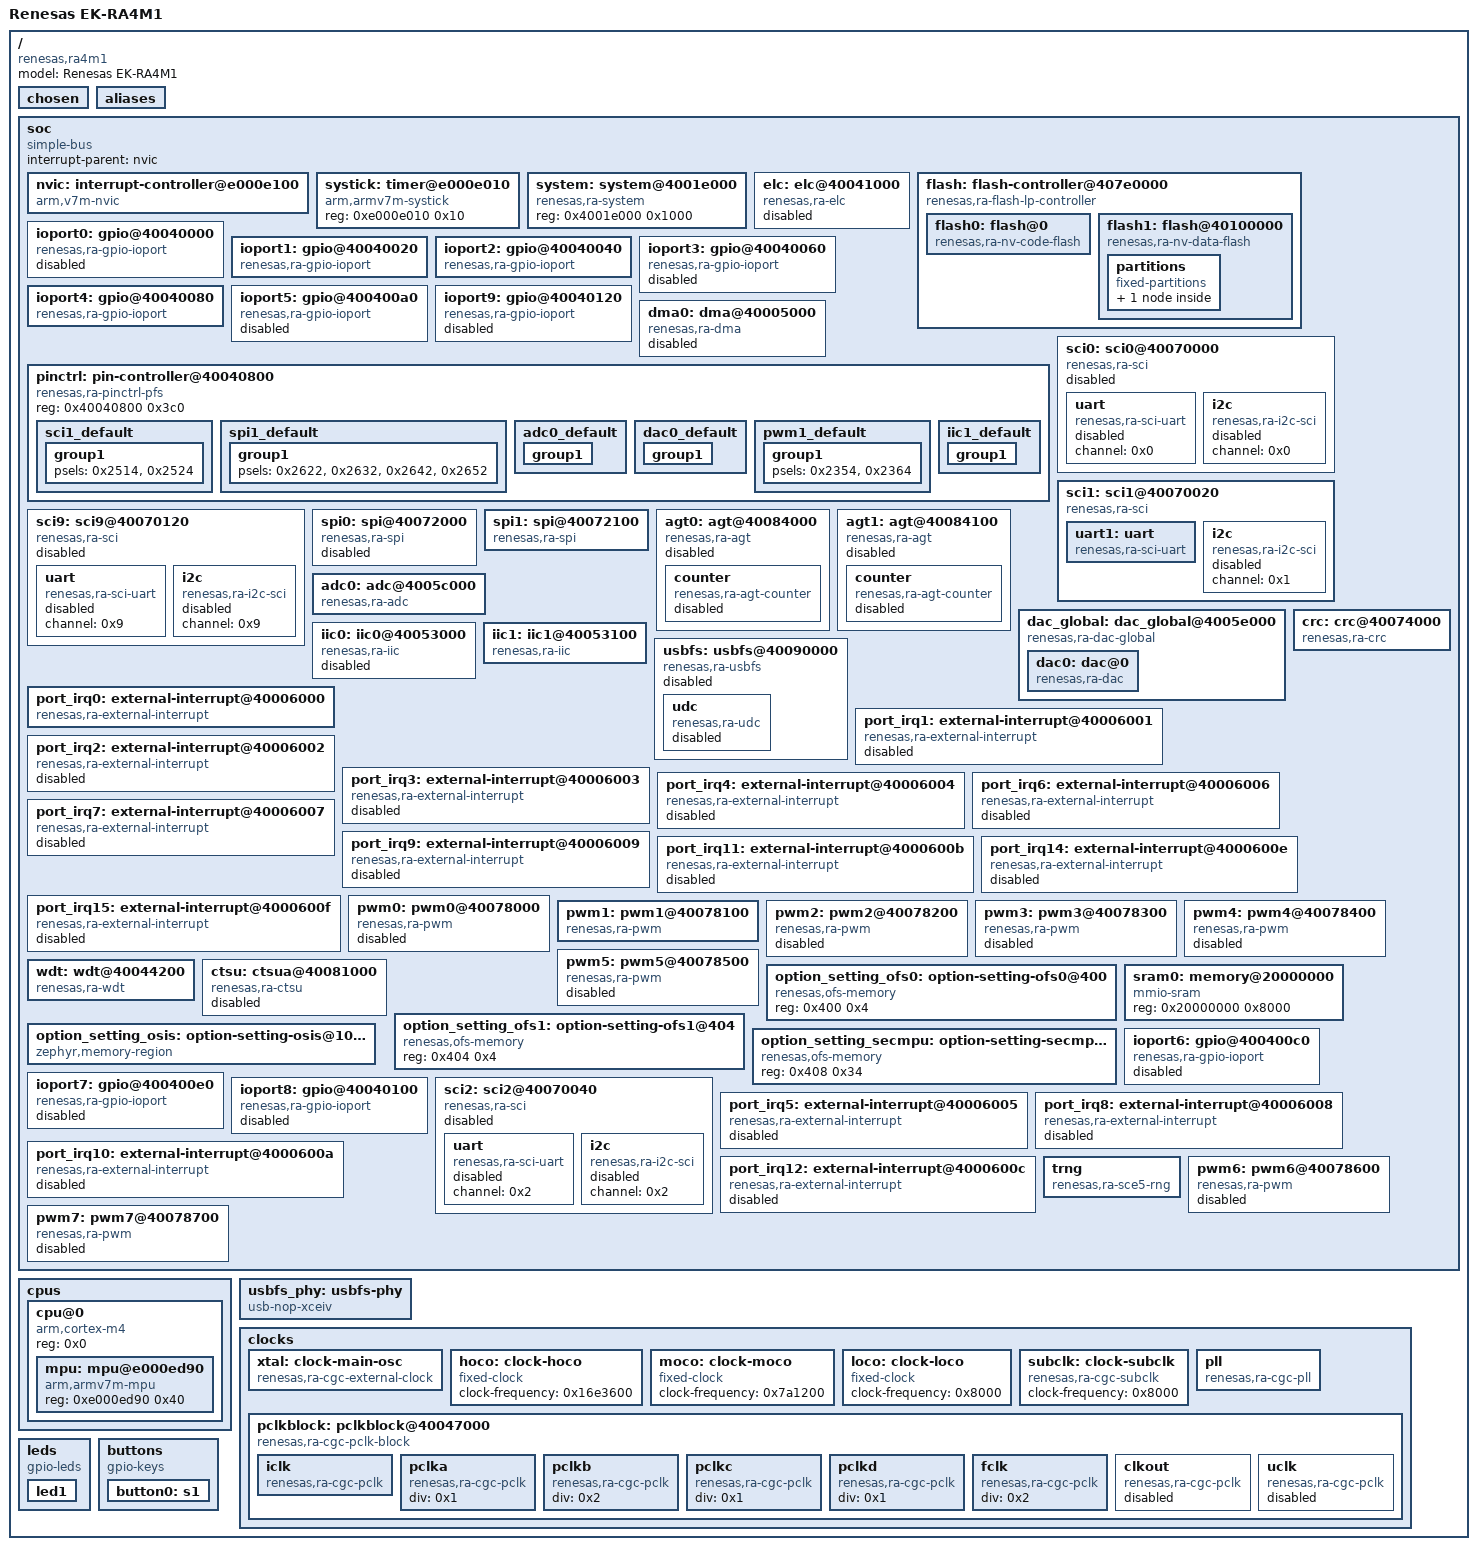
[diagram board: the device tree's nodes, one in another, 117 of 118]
/dts-v1/;

/* node '/' defined in zephyr/dts/common/skeleton.dtsi:9 */
/ {
	#address-cells = < 0x1 >;     /* in zephyr/dts/common/skeleton.dtsi:10 */
	#size-cells = < 0x1 >;        /* in zephyr/dts/common/skeleton.dtsi:11 */
	model = "Renesas EK-RA4M1";   /* in zephyr/boards/renesas/ek_ra4m1/ek_ra4m1.dts:15 */
	compatible = "renesas,ra4m1",
	             "renesas,ra";    /* in zephyr/boards/renesas/ek_ra4m1/ek_ra4m1.dts:16 */

	/* node '/chosen' defined in zephyr/dts/common/skeleton.dtsi:13 */
	chosen {
		zephyr,sram = &sram0;             /* in zephyr/boards/renesas/ek_ra4m1/ek_ra4m1.dts:19 */
		zephyr,flash-controller = &flash; /* in zephyr/boards/renesas/ek_ra4m1/ek_ra4m1.dts:20 */
		zephyr,flash = &flash0;           /* in zephyr/boards/renesas/ek_ra4m1/ek_ra4m1.dts:21 */
		zephyr,console = &uart1;          /* in zephyr/boards/renesas/ek_ra4m1/ek_ra4m1.dts:22 */
		zephyr,shell-uart = &uart1;       /* in zephyr/boards/renesas/ek_ra4m1/ek_ra4m1.dts:23 */
		zephyr,entropy = &trng;           /* in zephyr/boards/renesas/ek_ra4m1/ek_ra4m1.dts:24 */
		zephyr,crc = &crc;                /* in zephyr/boards/renesas/ek_ra4m1/ek_ra4m1.dts:25 */
	};

	/* node '/aliases' defined in zephyr/dts/common/skeleton.dtsi:15 */
	aliases {
		led0 = &led1;     /* in zephyr/boards/renesas/ek_ra4m1/ek_ra4m1.dts:48 */
		sw0 = &button0;   /* in zephyr/boards/renesas/ek_ra4m1/ek_ra4m1.dts:49 */
		watchdog0 = &wdt; /* in zephyr/boards/renesas/ek_ra4m1/ek_ra4m1.dts:50 */
	};

	/* node '/soc' defined in zephyr/dts/arm/armv7-m.dtsi:6 */
	soc {
		#address-cells = < 0x1 >;     /* in zephyr/dts/arm/armv7-m.dtsi:7 */
		#size-cells = < 0x1 >;        /* in zephyr/dts/arm/armv7-m.dtsi:8 */
		compatible = "simple-bus";    /* in zephyr/dts/arm/armv7-m.dtsi:9 */
		interrupt-parent = < &nvic >; /* in zephyr/dts/arm/armv7-m.dtsi:10 */
		ranges;                       /* in zephyr/dts/arm/armv7-m.dtsi:11 */

		/* node '/soc/interrupt-controller@e000e100' defined in zephyr/dts/arm/armv7-m.dtsi:13 */
		nvic: interrupt-controller@e000e100 {
			#address-cells = < 0x1 >;            /* in zephyr/dts/arm/armv7-m.dtsi:14 */
			compatible = "arm,v7m-nvic";         /* in zephyr/dts/arm/armv7-m.dtsi:15 */
			reg = < 0xe000e100 0xc00 >;          /* in zephyr/dts/arm/armv7-m.dtsi:16 */
			interrupt-controller;                /* in zephyr/dts/arm/armv7-m.dtsi:17 */
			#interrupt-cells = < 0x2 >;          /* in zephyr/dts/arm/armv7-m.dtsi:18 */
			arm,num-irq-priority-bits = < 0x4 >; /* in zephyr/dts/arm/renesas/ra/ra4/ra4-cm4-common.dtsi:526 */
			phandle = < 0x1 >;                   /* in zephyr/dts/arm/armv7-m.dtsi:10 */
		};

		/* node '/soc/timer@e000e010' defined in zephyr/dts/arm/armv7-m.dtsi:21 */
		systick: timer@e000e010 {
			compatible = "arm,armv7m-systick"; /* in zephyr/dts/arm/armv7-m.dtsi:22 */
			reg = < 0xe000e010 0x10 >;         /* in zephyr/dts/arm/armv7-m.dtsi:23 */
		};

		/* node '/soc/system@4001e000' defined in zephyr/dts/arm/renesas/ra/ra4/ra4-cm4-common.dtsi:33 */
		system: system@4001e000 {
			compatible = "renesas,ra-system"; /* in zephyr/dts/arm/renesas/ra/ra4/ra4-cm4-common.dtsi:34 */
			reg = < 0x4001e000 0x1000 >;      /* in zephyr/dts/arm/renesas/ra/ra4/ra4-cm4-common.dtsi:35 */
			status = "okay";                  /* in zephyr/dts/arm/renesas/ra/ra4/ra4-cm4-common.dtsi:36 */
		};

		/* node '/soc/elc@40041000' defined in zephyr/dts/arm/renesas/ra/ra4/ra4-cm4-common.dtsi:39 */
		elc: elc@40041000 {
			compatible = "renesas,ra-elc"; /* in zephyr/dts/arm/renesas/ra/ra4/ra4-cm4-common.dtsi:40 */
			reg = < 0x40041000 0x70 >;     /* in zephyr/dts/arm/renesas/ra/ra4/ra4-cm4-common.dtsi:41 */
			#renesas-elc-cells = < 0x2 >;  /* in zephyr/dts/arm/renesas/ra/ra4/ra4-cm4-common.dtsi:42 */
			clocks = < &pclkb 0x2 0xe >;   /* in zephyr/dts/arm/renesas/ra/ra4/ra4-cm4-common.dtsi:43 */
			status = "disabled";           /* in zephyr/dts/arm/renesas/ra/ra4/ra4-cm4-common.dtsi:44 */
		};

		/* node '/soc/flash-controller@407e0000' defined in zephyr/dts/arm/renesas/ra/ra4/ra4-cm4-common.dtsi:47 */
		flash: flash-controller@407e0000 {
			compatible = "renesas,ra-flash-lp-controller"; /* in zephyr/dts/arm/renesas/ra/ra4/ra4-cm4-common.dtsi:48 */
			reg = < 0x407e0000 0x10000 >;                  /* in zephyr/dts/arm/renesas/ra/ra4/ra4-cm4-common.dtsi:49 */
			#address-cells = < 0x1 >;                      /* in zephyr/dts/arm/renesas/ra/ra4/ra4-cm4-common.dtsi:50 */
			#size-cells = < 0x1 >;                         /* in zephyr/dts/arm/renesas/ra/ra4/ra4-cm4-common.dtsi:51 */
			interrupts = < 0x17 0x1 >;                     /* in zephyr/dts/arm/renesas/ra/ra4/ra4-cm4-common.dtsi:52 */
			interrupt-names = "frdyi";                     /* in zephyr/dts/arm/renesas/ra/ra4/ra4-cm4-common.dtsi:53 */
			flash-hardware-version = < 0x3 >;              /* in zephyr/dts/arm/renesas/ra/ra4/r7fa4m1ab3cfp.dtsi:14 */
			#erase-block-cells = < 0x2 >;                  /* in zephyr/dts/arm/renesas/ra/ra4/r7fa4m1ab3cfp.dtsi:15 */
			phandle = < 0x3 >;                             /* in zephyr/dts/arm/renesas/ra/ra4/r7fa4m1ab3cfp.dtsi:22 */

			/* node '/soc/flash-controller@407e0000/flash@0' defined in zephyr/dts/arm/renesas/ra/ra4/r7fa4m1ab3cfp.dtsi:17 */
			flash0: flash@0 {
				compatible = "renesas,ra-nv-code-flash"; /* in zephyr/dts/arm/renesas/ra/ra4/r7fa4m1ab3cfp.dtsi:18 */
				reg = < 0x0 0x40000 >;                   /* in zephyr/dts/arm/renesas/ra/ra4/r7fa4m1ab3cfp.dtsi:19 */
				write-block-size = < 0x8 >;              /* in zephyr/dts/arm/renesas/ra/ra4/r7fa4m1ab3cfp.dtsi:20 */
				erase-block-size = < 0x800 >;            /* in zephyr/dts/arm/renesas/ra/ra4/r7fa4m1ab3cfp.dtsi:21 */
				erase-blocks = < &flash 0x80 0x800 >;    /* in zephyr/dts/arm/renesas/ra/ra4/r7fa4m1ab3cfp.dtsi:22 */
				programming-enable;                      /* in zephyr/dts/arm/renesas/ra/ra4/r7fa4m1ab3cfp.dtsi:23 */
			};

			/* node '/soc/flash-controller@407e0000/flash@40100000' defined in zephyr/dts/arm/renesas/ra/ra4/r7fa4m1ab3cfp.dtsi:26 */
			flash1: flash@40100000 {
				compatible = "renesas,ra-nv-data-flash"; /* in zephyr/dts/arm/renesas/ra/ra4/r7fa4m1ab3cfp.dtsi:27 */
				reg = < 0x40100000 0x2000 >;             /* in zephyr/dts/arm/renesas/ra/ra4/r7fa4m1ab3cfp.dtsi:28 */
				write-block-size = < 0x1 >;              /* in zephyr/dts/arm/renesas/ra/ra4/r7fa4m1ab3cfp.dtsi:29 */
				erase-block-size = < 0x400 >;            /* in zephyr/dts/arm/renesas/ra/ra4/r7fa4m1ab3cfp.dtsi:30 */
				programming-enable;                      /* in zephyr/dts/arm/renesas/ra/ra4/r7fa4m1ab3cfp.dtsi:31 */

				/* node '/soc/flash-controller@407e0000/flash@40100000/partitions' defined in zephyr/boards/renesas/ek_ra4m1/ek_ra4m1.dts:150 */
				partitions {
					compatible = "fixed-partitions"; /* in zephyr/boards/renesas/ek_ra4m1/ek_ra4m1.dts:151 */
					#address-cells = < 0x1 >;        /* in zephyr/boards/renesas/ek_ra4m1/ek_ra4m1.dts:152 */
					#size-cells = < 0x1 >;           /* in zephyr/boards/renesas/ek_ra4m1/ek_ra4m1.dts:153 */

					/* node '/soc/flash-controller@407e0000/flash@40100000/partitions/partition@0' defined in zephyr/boards/renesas/ek_ra4m1/ek_ra4m1.dts:155 */
					storage_partition: partition@0 {
						label = "storage";    /* in zephyr/boards/renesas/ek_ra4m1/ek_ra4m1.dts:156 */
						reg = < 0x0 0x2000 >; /* in zephyr/boards/renesas/ek_ra4m1/ek_ra4m1.dts:157 */
					};
				};
			};
		};

		/* node '/soc/gpio@40040000' defined in zephyr/dts/arm/renesas/ra/ra4/ra4-cm4-common.dtsi:56 */
		ioport0: gpio@40040000 {
			compatible = "renesas,ra-gpio-ioport";                                               /* in zephyr/dts/arm/renesas/ra/ra4/ra4-cm4-common.dtsi:57 */
			reg = < 0x40040000 0x20 >;                                                           /* in zephyr/dts/arm/renesas/ra/ra4/ra4-cm4-common.dtsi:58 */
			port = < 0x0 >;                                                                      /* in zephyr/dts/arm/renesas/ra/ra4/ra4-cm4-common.dtsi:59 */
			gpio-controller;                                                                     /* in zephyr/dts/arm/renesas/ra/ra4/ra4-cm4-common.dtsi:60 */
			#gpio-cells = < 0x2 >;                                                               /* in zephyr/dts/arm/renesas/ra/ra4/ra4-cm4-common.dtsi:61 */
			ngpios = < 0x10 >;                                                                   /* in zephyr/dts/arm/renesas/ra/ra4/ra4-cm4-common.dtsi:62 */
			status = "disabled";                                                                 /* in zephyr/dts/arm/renesas/ra/ra4/ra4-cm4-common.dtsi:63 */
			port-irqs = < &port_irq2 &port_irq3 &port_irq6 &port_irq7 &port_irq10 &port_irq15 >; /* in zephyr/dts/arm/renesas/ra/ra4/r7fa4m1ax.dtsi:253 */
			port-irq-names = "port-irq2",
			                 "port-irq3",
			                 "port-irq6",
			                 "port-irq7",
			                 "port-irq10",
			                 "port-irq15";                                                       /* in zephyr/dts/arm/renesas/ra/ra4/r7fa4m1ax.dtsi:255 */
			port-irq2-pins = < 0x2 >;                                                            /* in zephyr/dts/arm/renesas/ra/ra4/r7fa4m1ax.dtsi:261 */
			port-irq3-pins = < 0x4 >;                                                            /* in zephyr/dts/arm/renesas/ra/ra4/r7fa4m1ax.dtsi:262 */
			port-irq6-pins = < 0x0 >;                                                            /* in zephyr/dts/arm/renesas/ra/ra4/r7fa4m1ax.dtsi:263 */
			port-irq7-pins = < 0x1 0xf >;                                                        /* in zephyr/dts/arm/renesas/ra/ra4/r7fa4m1ax.dtsi:264 */
			port-irq10-pins = < 0x5 >;                                                           /* in zephyr/dts/arm/renesas/ra/ra4/r7fa4m1ax.dtsi:265 */
			port-irq15-pins = < 0xb >;                                                           /* in zephyr/dts/arm/renesas/ra/ra4/r7fa4m1ax.dtsi:266 */
		};

		/* node '/soc/gpio@40040020' defined in zephyr/dts/arm/renesas/ra/ra4/ra4-cm4-common.dtsi:66 */
		ioport1: gpio@40040020 {
			compatible = "renesas,ra-gpio-ioport";                                  /* in zephyr/dts/arm/renesas/ra/ra4/ra4-cm4-common.dtsi:67 */
			reg = < 0x40040020 0x20 >;                                              /* in zephyr/dts/arm/renesas/ra/ra4/ra4-cm4-common.dtsi:68 */
			port = < 0x1 >;                                                         /* in zephyr/dts/arm/renesas/ra/ra4/ra4-cm4-common.dtsi:69 */
			gpio-controller;                                                        /* in zephyr/dts/arm/renesas/ra/ra4/ra4-cm4-common.dtsi:70 */
			#gpio-cells = < 0x2 >;                                                  /* in zephyr/dts/arm/renesas/ra/ra4/ra4-cm4-common.dtsi:71 */
			ngpios = < 0x10 >;                                                      /* in zephyr/dts/arm/renesas/ra/ra4/ra4-cm4-common.dtsi:72 */
			port-irqs = < &port_irq0 &port_irq1 &port_irq2 &port_irq3 &port_irq4 >; /* in zephyr/dts/arm/renesas/ra/ra4/r7fa4m1ax.dtsi:270 */
			port-irq-names = "port-irq0",
			                 "port-irq1",
			                 "port-irq2",
			                 "port-irq3",
			                 "port-irq4";                                           /* in zephyr/dts/arm/renesas/ra/ra4/r7fa4m1ax.dtsi:272 */
			port-irq0-pins = < 0x5 >;                                               /* in zephyr/dts/arm/renesas/ra/ra4/r7fa4m1ax.dtsi:277 */
			port-irq1-pins = < 0x1 0x4 >;                                           /* in zephyr/dts/arm/renesas/ra/ra4/r7fa4m1ax.dtsi:278 */
			port-irq2-pins = < 0x0 >;                                               /* in zephyr/dts/arm/renesas/ra/ra4/r7fa4m1ax.dtsi:279 */
			port-irq3-pins = < 0xa >;                                               /* in zephyr/dts/arm/renesas/ra/ra4/r7fa4m1ax.dtsi:280 */
			port-irq4-pins = < 0xb >;                                               /* in zephyr/dts/arm/renesas/ra/ra4/r7fa4m1ax.dtsi:281 */
			status = "okay";                                                        /* in zephyr/boards/renesas/ek_ra4m1/ek_ra4m1.dts:84 */
			phandle = < 0x20 >;                                                     /* in zephyr/boards/renesas/ek_ra4m1/ek_ra4m1.dts:32 */
		};

		/* node '/soc/gpio@40040040' defined in zephyr/dts/arm/renesas/ra/ra4/ra4-cm4-common.dtsi:76 */
		ioport2: gpio@40040040 {
			compatible = "renesas,ra-gpio-ioport";                       /* in zephyr/dts/arm/renesas/ra/ra4/ra4-cm4-common.dtsi:77 */
			reg = < 0x40040040 0x20 >;                                   /* in zephyr/dts/arm/renesas/ra/ra4/ra4-cm4-common.dtsi:78 */
			port = < 0x2 >;                                              /* in zephyr/dts/arm/renesas/ra/ra4/ra4-cm4-common.dtsi:79 */
			gpio-controller;                                             /* in zephyr/dts/arm/renesas/ra/ra4/ra4-cm4-common.dtsi:80 */
			#gpio-cells = < 0x2 >;                                       /* in zephyr/dts/arm/renesas/ra/ra4/ra4-cm4-common.dtsi:81 */
			ngpios = < 0x10 >;                                           /* in zephyr/dts/arm/renesas/ra/ra4/ra4-cm4-common.dtsi:82 */
			port-irqs = < &port_irq0 &port_irq1 &port_irq2 &port_irq3 >; /* in zephyr/dts/arm/renesas/ra/ra4/r7fa4m1ax.dtsi:285 */
			port-irq-names = "port-irq0",
			                 "port-irq1",
			                 "port-irq2",
			                 "port-irq3";                                /* in zephyr/dts/arm/renesas/ra/ra4/r7fa4m1ax.dtsi:287 */
			port-irq0-pins = < 0x6 >;                                    /* in zephyr/dts/arm/renesas/ra/ra4/r7fa4m1ax.dtsi:291 */
			port-irq1-pins = < 0x5 >;                                    /* in zephyr/dts/arm/renesas/ra/ra4/r7fa4m1ax.dtsi:292 */
			port-irq2-pins = < 0xd >;                                    /* in zephyr/dts/arm/renesas/ra/ra4/r7fa4m1ax.dtsi:293 */
			port-irq3-pins = < 0xc >;                                    /* in zephyr/dts/arm/renesas/ra/ra4/r7fa4m1ax.dtsi:294 */
			status = "okay";                                             /* in zephyr/boards/renesas/ek_ra4m1/ek_ra4m1.dts:88 */
		};

		/* node '/soc/gpio@40040060' defined in zephyr/dts/arm/renesas/ra/ra4/ra4-cm4-common.dtsi:86 */
		ioport3: gpio@40040060 {
			compatible = "renesas,ra-gpio-ioport";                       /* in zephyr/dts/arm/renesas/ra/ra4/ra4-cm4-common.dtsi:87 */
			reg = < 0x40040060 0x20 >;                                   /* in zephyr/dts/arm/renesas/ra/ra4/ra4-cm4-common.dtsi:88 */
			port = < 0x3 >;                                              /* in zephyr/dts/arm/renesas/ra/ra4/ra4-cm4-common.dtsi:89 */
			gpio-controller;                                             /* in zephyr/dts/arm/renesas/ra/ra4/ra4-cm4-common.dtsi:90 */
			#gpio-cells = < 0x2 >;                                       /* in zephyr/dts/arm/renesas/ra/ra4/ra4-cm4-common.dtsi:91 */
			ngpios = < 0x10 >;                                           /* in zephyr/dts/arm/renesas/ra/ra4/ra4-cm4-common.dtsi:92 */
			status = "disabled";                                         /* in zephyr/dts/arm/renesas/ra/ra4/ra4-cm4-common.dtsi:93 */
			port-irqs = < &port_irq5 &port_irq6 &port_irq8 &port_irq9 >; /* in zephyr/dts/arm/renesas/ra/ra4/r7fa4m1ax.dtsi:298 */
			port-irq-names = "port-irq5",
			                 "port-irq6",
			                 "port-irq8",
			                 "port-irq9";                                /* in zephyr/dts/arm/renesas/ra/ra4/r7fa4m1ax.dtsi:300 */
			port-irq5-pins = < 0x2 >;                                    /* in zephyr/dts/arm/renesas/ra/ra4/r7fa4m1ax.dtsi:304 */
			port-irq6-pins = < 0x1 >;                                    /* in zephyr/dts/arm/renesas/ra/ra4/r7fa4m1ax.dtsi:305 */
			port-irq8-pins = < 0x5 >;                                    /* in zephyr/dts/arm/renesas/ra/ra4/r7fa4m1ax.dtsi:306 */
			port-irq9-pins = < 0x4 >;                                    /* in zephyr/dts/arm/renesas/ra/ra4/r7fa4m1ax.dtsi:307 */
		};

		/* node '/soc/gpio@40040080' defined in zephyr/dts/arm/renesas/ra/ra4/ra4-cm4-common.dtsi:96 */
		ioport4: gpio@40040080 {
			compatible = "renesas,ra-gpio-ioport";                                                        /* in zephyr/dts/arm/renesas/ra/ra4/ra4-cm4-common.dtsi:97 */
			reg = < 0x40040080 0x20 >;                                                                    /* in zephyr/dts/arm/renesas/ra/ra4/ra4-cm4-common.dtsi:98 */
			port = < 0x4 >;                                                                               /* in zephyr/dts/arm/renesas/ra/ra4/ra4-cm4-common.dtsi:99 */
			gpio-controller;                                                                              /* in zephyr/dts/arm/renesas/ra/ra4/ra4-cm4-common.dtsi:100 */
			#gpio-cells = < 0x2 >;                                                                        /* in zephyr/dts/arm/renesas/ra/ra4/ra4-cm4-common.dtsi:101 */
			ngpios = < 0x10 >;                                                                            /* in zephyr/dts/arm/renesas/ra/ra4/ra4-cm4-common.dtsi:102 */
			vbatts-pins = < 0x2 0x3 0x4 >;                                                                /* in zephyr/dts/arm/renesas/ra/ra4/ra4-cm4-common.dtsi:103 */
			port-irqs = < &port_irq0 &port_irq4 &port_irq5 &port_irq6 &port_irq7 &port_irq8 &port_irq9 >; /* in zephyr/dts/arm/renesas/ra/ra4/r7fa4m1ax.dtsi:311 */
			port-irq-names = "port-irq0",
			                 "port-irq4",
			                 "port-irq5",
			                 "port-irq6",
			                 "port-irq7",
			                 "port-irq8",
			                 "port-irq9";                                                                 /* in zephyr/dts/arm/renesas/ra/ra4/r7fa4m1ax.dtsi:314 */
			port-irq0-pins = < 0x0 >;                                                                     /* in zephyr/dts/arm/renesas/ra/ra4/r7fa4m1ax.dtsi:321 */
			port-irq4-pins = < 0x2 0xb >;                                                                 /* in zephyr/dts/arm/renesas/ra/ra4/r7fa4m1ax.dtsi:322 */
			port-irq5-pins = < 0x1 0xa >;                                                                 /* in zephyr/dts/arm/renesas/ra/ra4/r7fa4m1ax.dtsi:323 */
			port-irq6-pins = < 0x9 >;                                                                     /* in zephyr/dts/arm/renesas/ra/ra4/r7fa4m1ax.dtsi:324 */
			port-irq7-pins = < 0x8 >;                                                                     /* in zephyr/dts/arm/renesas/ra/ra4/r7fa4m1ax.dtsi:325 */
			port-irq8-pins = < 0xf >;                                                                     /* in zephyr/dts/arm/renesas/ra/ra4/r7fa4m1ax.dtsi:326 */
			port-irq9-pins = < 0xe >;                                                                     /* in zephyr/dts/arm/renesas/ra/ra4/r7fa4m1ax.dtsi:327 */
			status = "okay";                                                                              /* in zephyr/boards/renesas/ek_ra4m1/ek_ra4m1.dts:92 */
		};

		/* node '/soc/gpio@400400a0' defined in zephyr/dts/arm/renesas/ra/ra4/ra4-cm4-common.dtsi:107 */
		ioport5: gpio@400400a0 {
			compatible = "renesas,ra-gpio-ioport";               /* in zephyr/dts/arm/renesas/ra/ra4/ra4-cm4-common.dtsi:108 */
			reg = < 0x400400a0 0x20 >;                           /* in zephyr/dts/arm/renesas/ra/ra4/ra4-cm4-common.dtsi:109 */
			port = < 0x5 >;                                      /* in zephyr/dts/arm/renesas/ra/ra4/ra4-cm4-common.dtsi:110 */
			gpio-controller;                                     /* in zephyr/dts/arm/renesas/ra/ra4/ra4-cm4-common.dtsi:111 */
			#gpio-cells = < 0x2 >;                               /* in zephyr/dts/arm/renesas/ra/ra4/ra4-cm4-common.dtsi:112 */
			ngpios = < 0x10 >;                                   /* in zephyr/dts/arm/renesas/ra/ra4/ra4-cm4-common.dtsi:113 */
			status = "disabled";                                 /* in zephyr/dts/arm/renesas/ra/ra4/ra4-cm4-common.dtsi:114 */
			port-irqs = < &port_irq11 &port_irq12 &port_irq14 >; /* in zephyr/dts/arm/renesas/ra/ra4/r7fa4m1ax.dtsi:331 */
			port-irq-names = "port-irq11",
			                 "port-irq12",
			                 "port-irq14";                       /* in zephyr/dts/arm/renesas/ra/ra4/r7fa4m1ax.dtsi:332 */
			port-irq11-pins = < 0x1 >;                           /* in zephyr/dts/arm/renesas/ra/ra4/r7fa4m1ax.dtsi:335 */
			port-irq12-pins = < 0x2 >;                           /* in zephyr/dts/arm/renesas/ra/ra4/r7fa4m1ax.dtsi:336 */
			port-irq14-pins = < 0x5 >;                           /* in zephyr/dts/arm/renesas/ra/ra4/r7fa4m1ax.dtsi:337 */
		};

		/* node '/soc/gpio@40040120' defined in zephyr/dts/arm/renesas/ra/ra4/ra4-cm4-common.dtsi:117 */
		ioport9: gpio@40040120 {
			compatible = "renesas,ra-gpio-ioport"; /* in zephyr/dts/arm/renesas/ra/ra4/ra4-cm4-common.dtsi:118 */
			reg = < 0x40040120 0x20 >;             /* in zephyr/dts/arm/renesas/ra/ra4/ra4-cm4-common.dtsi:119 */
			port = < 0x9 >;                        /* in zephyr/dts/arm/renesas/ra/ra4/ra4-cm4-common.dtsi:120 */
			gpio-controller;                       /* in zephyr/dts/arm/renesas/ra/ra4/ra4-cm4-common.dtsi:121 */
			#gpio-cells = < 0x2 >;                 /* in zephyr/dts/arm/renesas/ra/ra4/ra4-cm4-common.dtsi:122 */
			ngpios = < 0x10 >;                     /* in zephyr/dts/arm/renesas/ra/ra4/ra4-cm4-common.dtsi:123 */
			status = "disabled";                   /* in zephyr/dts/arm/renesas/ra/ra4/ra4-cm4-common.dtsi:124 */
		};

		/* node '/soc/dma@40005000' defined in zephyr/dts/arm/renesas/ra/ra4/ra4-cm4-common.dtsi:127 */
		dma0: dma@40005000 {
			compatible = "renesas,ra-dma"; /* in zephyr/dts/arm/renesas/ra/ra4/ra4-cm4-common.dtsi:128 */
			reg = < 0x40005000 0x100 >,
			      < 0x40005200 0xa0 >;     /* in zephyr/dts/arm/renesas/ra/ra4/ra4-cm4-common.dtsi:129 */
			reg-names = "channel",
			            "common";          /* in zephyr/dts/arm/renesas/ra/ra4/ra4-cm4-common.dtsi:130 */
			clocks = < &iclk 0x0 0x16 >;   /* in zephyr/dts/arm/renesas/ra/ra4/ra4-cm4-common.dtsi:131 */
			dma-channels = < 0x4 >;        /* in zephyr/dts/arm/renesas/ra/ra4/ra4-cm4-common.dtsi:132 */
			#dma-cells = < 0x2 >;          /* in zephyr/dts/arm/renesas/ra/ra4/ra4-cm4-common.dtsi:133 */
			status = "disabled";           /* in zephyr/dts/arm/renesas/ra/ra4/ra4-cm4-common.dtsi:134 */
		};

		/* node '/soc/pin-controller@40040800' defined in zephyr/dts/arm/renesas/ra/ra4/ra4-cm4-common.dtsi:137 */
		pinctrl: pin-controller@40040800 {
			compatible = "renesas,ra-pinctrl-pfs"; /* in zephyr/dts/arm/renesas/ra/ra4/ra4-cm4-common.dtsi:138 */
			reg = < 0x40040800 0x3c0 >;            /* in zephyr/dts/arm/renesas/ra/ra4/ra4-cm4-common.dtsi:139 */
			status = "okay";                       /* in zephyr/dts/arm/renesas/ra/ra4/ra4-cm4-common.dtsi:140 */

			/* node '/soc/pin-controller@40040800/sci1_default' defined in zephyr/boards/renesas/ek_ra4m1/ek_ra4m1-pinctrl.dtsi:7 */
			sci1_default: sci1_default {
				phandle = < 0x15 >; /* in zephyr/boards/renesas/ek_ra4m1/ek_ra4m1.dts:73 */

				/* node '/soc/pin-controller@40040800/sci1_default/group1' defined in zephyr/boards/renesas/ek_ra4m1/ek_ra4m1-pinctrl.dtsi:8 */
				group1 {
					psels = < 0x2514 >,
					        < 0x2524 >; /* in zephyr/boards/renesas/ek_ra4m1/ek_ra4m1-pinctrl.dtsi:10 */
				};
			};

			/* node '/soc/pin-controller@40040800/spi1_default' defined in zephyr/boards/renesas/ek_ra4m1/ek_ra4m1-pinctrl.dtsi:15 */
			spi1_default: spi1_default {
				phandle = < 0x16 >; /* in zephyr/boards/renesas/ek_ra4m1/ek_ra4m1.dts:96 */

				/* node '/soc/pin-controller@40040800/spi1_default/group1' defined in zephyr/boards/renesas/ek_ra4m1/ek_ra4m1-pinctrl.dtsi:16 */
				group1 {
					psels = < 0x2622 >,
					        < 0x2632 >,
					        < 0x2642 >,
					        < 0x2652 >; /* in zephyr/boards/renesas/ek_ra4m1/ek_ra4m1-pinctrl.dtsi:18 */
				};
			};

			/* node '/soc/pin-controller@40040800/adc0_default' defined in zephyr/boards/renesas/ek_ra4m1/ek_ra4m1-pinctrl.dtsi:25 */
			adc0_default: adc0_default {
				phandle = < 0x17 >; /* in zephyr/boards/renesas/ek_ra4m1/ek_ra4m1.dts:103 */

				/* node '/soc/pin-controller@40040800/adc0_default/group1' defined in zephyr/boards/renesas/ek_ra4m1/ek_ra4m1-pinctrl.dtsi:26 */
				group1 {
					psels = < 0x2000 >;    /* in zephyr/boards/renesas/ek_ra4m1/ek_ra4m1-pinctrl.dtsi:28 */
					renesas,analog-enable; /* in zephyr/boards/renesas/ek_ra4m1/ek_ra4m1-pinctrl.dtsi:29 */
				};
			};

			/* node '/soc/pin-controller@40040800/dac0_default' defined in zephyr/boards/renesas/ek_ra4m1/ek_ra4m1-pinctrl.dtsi:33 */
			dac0_default: dac0_default {
				phandle = < 0x18 >; /* in zephyr/boards/renesas/ek_ra4m1/ek_ra4m1.dts:108 */

				/* node '/soc/pin-controller@40040800/dac0_default/group1' defined in zephyr/boards/renesas/ek_ra4m1/ek_ra4m1-pinctrl.dtsi:34 */
				group1 {
					psels = < 0x20e0 >;    /* in zephyr/boards/renesas/ek_ra4m1/ek_ra4m1-pinctrl.dtsi:36 */
					renesas,analog-enable; /* in zephyr/boards/renesas/ek_ra4m1/ek_ra4m1-pinctrl.dtsi:37 */
				};
			};

			/* node '/soc/pin-controller@40040800/pwm1_default' defined in zephyr/boards/renesas/ek_ra4m1/ek_ra4m1-pinctrl.dtsi:41 */
			pwm1_default: pwm1_default {
				phandle = < 0x1d >; /* in zephyr/boards/renesas/ek_ra4m1/ek_ra4m1.dts:123 */

				/* node '/soc/pin-controller@40040800/pwm1_default/group1' defined in zephyr/boards/renesas/ek_ra4m1/ek_ra4m1-pinctrl.dtsi:42 */
				group1 {
					psels = < 0x2354 >,
					        < 0x2364 >; /* in zephyr/boards/renesas/ek_ra4m1/ek_ra4m1-pinctrl.dtsi:44 */
				};
			};

			/* node '/soc/pin-controller@40040800/iic1_default' defined in zephyr/boards/renesas/ek_ra4m1/ek_ra4m1-pinctrl.dtsi:49 */
			iic1_default: iic1_default {
				phandle = < 0x19 >; /* in zephyr/boards/renesas/ek_ra4m1/ek_ra4m1.dts:131 */

				/* node '/soc/pin-controller@40040800/iic1_default/group1' defined in zephyr/boards/renesas/ek_ra4m1/ek_ra4m1-pinctrl.dtsi:50 */
				group1 {
					psels = < 0x2701 >,
					        < 0x2762 >;        /* in zephyr/boards/renesas/ek_ra4m1/ek_ra4m1-pinctrl.dtsi:52 */
					drive-strength = "medium"; /* in zephyr/boards/renesas/ek_ra4m1/ek_ra4m1-pinctrl.dtsi:54 */
				};
			};
		};

		/* node '/soc/sci0@40070000' defined in zephyr/dts/arm/renesas/ra/ra4/ra4-cm4-common.dtsi:143 */
		sci0: sci0@40070000 {
			compatible = "renesas,ra-sci"; /* in zephyr/dts/arm/renesas/ra/ra4/ra4-cm4-common.dtsi:144 */
			interrupts = < 0x0 0x1 >,
			             < 0x1 0x1 >,
			             < 0x2 0x1 >,
			             < 0x3 0x1 >;      /* in zephyr/dts/arm/renesas/ra/ra4/ra4-cm4-common.dtsi:145 */
			interrupt-names = "rxi",
			                  "txi",
			                  "tei",
			                  "eri";       /* in zephyr/dts/arm/renesas/ra/ra4/ra4-cm4-common.dtsi:146 */
			reg = < 0x40070000 0x20 >;     /* in zephyr/dts/arm/renesas/ra/ra4/ra4-cm4-common.dtsi:147 */
			clocks = < &pclka 0x1 0x1f >;  /* in zephyr/dts/arm/renesas/ra/ra4/ra4-cm4-common.dtsi:148 */
			status = "disabled";           /* in zephyr/dts/arm/renesas/ra/ra4/ra4-cm4-common.dtsi:149 */

			/* node '/soc/sci0@40070000/uart' defined in zephyr/dts/arm/renesas/ra/ra4/ra4-cm4-common.dtsi:151 */
			uart {
				compatible = "renesas,ra-sci-uart"; /* in zephyr/dts/arm/renesas/ra/ra4/ra4-cm4-common.dtsi:152 */
				channel = < 0x0 >;                  /* in zephyr/dts/arm/renesas/ra/ra4/ra4-cm4-common.dtsi:153 */
				status = "disabled";                /* in zephyr/dts/arm/renesas/ra/ra4/ra4-cm4-common.dtsi:154 */
			};

			/* node '/soc/sci0@40070000/i2c' defined in zephyr/dts/arm/renesas/ra/ra4/ra4-cm4-common.dtsi:157 */
			i2c {
				compatible = "renesas,ra-i2c-sci"; /* in zephyr/dts/arm/renesas/ra/ra4/ra4-cm4-common.dtsi:158 */
				#address-cells = < 0x1 >;          /* in zephyr/dts/arm/renesas/ra/ra4/ra4-cm4-common.dtsi:159 */
				#size-cells = < 0x0 >;             /* in zephyr/dts/arm/renesas/ra/ra4/ra4-cm4-common.dtsi:160 */
				channel = < 0x0 >;                 /* in zephyr/dts/arm/renesas/ra/ra4/ra4-cm4-common.dtsi:161 */
				status = "disabled";               /* in zephyr/dts/arm/renesas/ra/ra4/ra4-cm4-common.dtsi:162 */
			};
		};

		/* node '/soc/sci1@40070020' defined in zephyr/dts/arm/renesas/ra/ra4/ra4-cm4-common.dtsi:166 */
		sci1: sci1@40070020 {
			compatible = "renesas,ra-sci"; /* in zephyr/dts/arm/renesas/ra/ra4/ra4-cm4-common.dtsi:167 */
			interrupts = < 0x4 0x1 >,
			             < 0x5 0x1 >,
			             < 0x6 0x1 >,
			             < 0x7 0x1 >;      /* in zephyr/dts/arm/renesas/ra/ra4/ra4-cm4-common.dtsi:168 */
			interrupt-names = "rxi",
			                  "txi",
			                  "tei",
			                  "eri";       /* in zephyr/dts/arm/renesas/ra/ra4/ra4-cm4-common.dtsi:169 */
			reg = < 0x40070020 0x20 >;     /* in zephyr/dts/arm/renesas/ra/ra4/ra4-cm4-common.dtsi:170 */
			clocks = < &pclka 0x1 0x1e >;  /* in zephyr/dts/arm/renesas/ra/ra4/ra4-cm4-common.dtsi:171 */
			pinctrl-0 = < &sci1_default >; /* in zephyr/boards/renesas/ek_ra4m1/ek_ra4m1.dts:73 */
			pinctrl-names = "default";     /* in zephyr/boards/renesas/ek_ra4m1/ek_ra4m1.dts:74 */
			status = "okay";               /* in zephyr/boards/renesas/ek_ra4m1/ek_ra4m1.dts:75 */

			/* node '/soc/sci1@40070020/uart' defined in zephyr/dts/arm/renesas/ra/ra4/ra4-cm4-common.dtsi:174 */
			uart1: uart {
				compatible = "renesas,ra-sci-uart"; /* in zephyr/dts/arm/renesas/ra/ra4/ra4-cm4-common.dtsi:175 */
				channel = < 0x1 >;                  /* in zephyr/dts/arm/renesas/ra/ra4/ra4-cm4-common.dtsi:176 */
				current-speed = < 0x1c200 >;        /* in zephyr/boards/renesas/ek_ra4m1/ek_ra4m1.dts:78 */
				status = "okay";                    /* in zephyr/boards/renesas/ek_ra4m1/ek_ra4m1.dts:79 */
			};

			/* node '/soc/sci1@40070020/i2c' defined in zephyr/dts/arm/renesas/ra/ra4/ra4-cm4-common.dtsi:180 */
			i2c {
				compatible = "renesas,ra-i2c-sci"; /* in zephyr/dts/arm/renesas/ra/ra4/ra4-cm4-common.dtsi:181 */
				#address-cells = < 0x1 >;          /* in zephyr/dts/arm/renesas/ra/ra4/ra4-cm4-common.dtsi:182 */
				#size-cells = < 0x0 >;             /* in zephyr/dts/arm/renesas/ra/ra4/ra4-cm4-common.dtsi:183 */
				channel = < 0x1 >;                 /* in zephyr/dts/arm/renesas/ra/ra4/ra4-cm4-common.dtsi:184 */
				status = "disabled";               /* in zephyr/dts/arm/renesas/ra/ra4/ra4-cm4-common.dtsi:185 */
			};
		};

		/* node '/soc/sci9@40070120' defined in zephyr/dts/arm/renesas/ra/ra4/ra4-cm4-common.dtsi:189 */
		sci9: sci9@40070120 {
			compatible = "renesas,ra-sci"; /* in zephyr/dts/arm/renesas/ra/ra4/ra4-cm4-common.dtsi:190 */
			reg = < 0x40070120 0x20 >;     /* in zephyr/dts/arm/renesas/ra/ra4/ra4-cm4-common.dtsi:191 */
			clocks = < &pclka 0x1 0x16 >;  /* in zephyr/dts/arm/renesas/ra/ra4/ra4-cm4-common.dtsi:192 */
			status = "disabled";           /* in zephyr/dts/arm/renesas/ra/ra4/ra4-cm4-common.dtsi:193 */

			/* node '/soc/sci9@40070120/uart' defined in zephyr/dts/arm/renesas/ra/ra4/ra4-cm4-common.dtsi:195 */
			uart {
				compatible = "renesas,ra-sci-uart"; /* in zephyr/dts/arm/renesas/ra/ra4/ra4-cm4-common.dtsi:196 */
				channel = < 0x9 >;                  /* in zephyr/dts/arm/renesas/ra/ra4/ra4-cm4-common.dtsi:197 */
				status = "disabled";                /* in zephyr/dts/arm/renesas/ra/ra4/ra4-cm4-common.dtsi:198 */
			};

			/* node '/soc/sci9@40070120/i2c' defined in zephyr/dts/arm/renesas/ra/ra4/ra4-cm4-common.dtsi:201 */
			i2c {
				compatible = "renesas,ra-i2c-sci"; /* in zephyr/dts/arm/renesas/ra/ra4/ra4-cm4-common.dtsi:202 */
				#address-cells = < 0x1 >;          /* in zephyr/dts/arm/renesas/ra/ra4/ra4-cm4-common.dtsi:203 */
				#size-cells = < 0x0 >;             /* in zephyr/dts/arm/renesas/ra/ra4/ra4-cm4-common.dtsi:204 */
				channel = < 0x9 >;                 /* in zephyr/dts/arm/renesas/ra/ra4/ra4-cm4-common.dtsi:205 */
				status = "disabled";               /* in zephyr/dts/arm/renesas/ra/ra4/ra4-cm4-common.dtsi:206 */
			};
		};

		/* node '/soc/spi@40072000' defined in zephyr/dts/arm/renesas/ra/ra4/ra4-cm4-common.dtsi:210 */
		spi0: spi@40072000 {
			compatible = "renesas,ra-spi"; /* in zephyr/dts/arm/renesas/ra/ra4/ra4-cm4-common.dtsi:211 */
			#address-cells = < 0x1 >;      /* in zephyr/dts/arm/renesas/ra/ra4/ra4-cm4-common.dtsi:212 */
			#size-cells = < 0x0 >;         /* in zephyr/dts/arm/renesas/ra/ra4/ra4-cm4-common.dtsi:213 */
			channel = < 0x0 >;             /* in zephyr/dts/arm/renesas/ra/ra4/ra4-cm4-common.dtsi:214 */
			reg = < 0x40072000 0x100 >;    /* in zephyr/dts/arm/renesas/ra/ra4/ra4-cm4-common.dtsi:215 */
			status = "disabled";           /* in zephyr/dts/arm/renesas/ra/ra4/ra4-cm4-common.dtsi:216 */
		};

		/* node '/soc/spi@40072100' defined in zephyr/dts/arm/renesas/ra/ra4/ra4-cm4-common.dtsi:219 */
		spi1: spi@40072100 {
			compatible = "renesas,ra-spi"; /* in zephyr/dts/arm/renesas/ra/ra4/ra4-cm4-common.dtsi:220 */
			#address-cells = < 0x1 >;      /* in zephyr/dts/arm/renesas/ra/ra4/ra4-cm4-common.dtsi:221 */
			#size-cells = < 0x0 >;         /* in zephyr/dts/arm/renesas/ra/ra4/ra4-cm4-common.dtsi:222 */
			channel = < 0x1 >;             /* in zephyr/dts/arm/renesas/ra/ra4/ra4-cm4-common.dtsi:223 */
			interrupts = < 0x1c 0x1 >,
			             < 0x1d 0x1 >,
			             < 0x1e 0x1 >,
			             < 0x1f 0x1 >;     /* in zephyr/dts/arm/renesas/ra/ra4/ra4-cm4-common.dtsi:224 */
			interrupt-names = "rxi",
			                  "txi",
			                  "tei",
			                  "eri";       /* in zephyr/dts/arm/renesas/ra/ra4/ra4-cm4-common.dtsi:225 */
			reg = < 0x40072100 0x100 >;    /* in zephyr/dts/arm/renesas/ra/ra4/ra4-cm4-common.dtsi:226 */
			pinctrl-0 = < &spi1_default >; /* in zephyr/boards/renesas/ek_ra4m1/ek_ra4m1.dts:96 */
			pinctrl-names = "default";     /* in zephyr/boards/renesas/ek_ra4m1/ek_ra4m1.dts:97 */
			status = "okay";               /* in zephyr/boards/renesas/ek_ra4m1/ek_ra4m1.dts:98 */
		};

		/* node '/soc/agt@40084000' defined in zephyr/dts/arm/renesas/ra/ra4/ra4-cm4-common.dtsi:230 */
		agt0: agt@40084000 {
			compatible = "renesas,ra-agt";           /* in zephyr/dts/arm/renesas/ra/ra4/ra4-cm4-common.dtsi:231 */
			channel = < 0x0 >;                       /* in zephyr/dts/arm/renesas/ra/ra4/ra4-cm4-common.dtsi:232 */
			reg = < 0x40084000 0x100 >;              /* in zephyr/dts/arm/renesas/ra/ra4/ra4-cm4-common.dtsi:233 */
			renesas,count-source = "AGT_CLOCK_LOCO"; /* in zephyr/dts/arm/renesas/ra/ra4/ra4-cm4-common.dtsi:234 */
			renesas,prescaler = < 0x0 >;             /* in zephyr/dts/arm/renesas/ra/ra4/ra4-cm4-common.dtsi:235 */
			renesas,resolution = < 0x10 >;           /* in zephyr/dts/arm/renesas/ra/ra4/ra4-cm4-common.dtsi:236 */
			status = "disabled";                     /* in zephyr/dts/arm/renesas/ra/ra4/ra4-cm4-common.dtsi:237 */

			/* node '/soc/agt@40084000/counter' defined in zephyr/dts/arm/renesas/ra/ra4/ra4-cm4-common.dtsi:239 */
			counter {
				compatible = "renesas,ra-agt-counter"; /* in zephyr/dts/arm/renesas/ra/ra4/ra4-cm4-common.dtsi:240 */
				status = "disabled";                   /* in zephyr/dts/arm/renesas/ra/ra4/ra4-cm4-common.dtsi:241 */
			};
		};

		/* node '/soc/agt@40084100' defined in zephyr/dts/arm/renesas/ra/ra4/ra4-cm4-common.dtsi:245 */
		agt1: agt@40084100 {
			compatible = "renesas,ra-agt";           /* in zephyr/dts/arm/renesas/ra/ra4/ra4-cm4-common.dtsi:246 */
			channel = < 0x1 >;                       /* in zephyr/dts/arm/renesas/ra/ra4/ra4-cm4-common.dtsi:247 */
			reg = < 0x40084100 0x100 >;              /* in zephyr/dts/arm/renesas/ra/ra4/ra4-cm4-common.dtsi:248 */
			renesas,count-source = "AGT_CLOCK_LOCO"; /* in zephyr/dts/arm/renesas/ra/ra4/ra4-cm4-common.dtsi:249 */
			renesas,prescaler = < 0x0 >;             /* in zephyr/dts/arm/renesas/ra/ra4/ra4-cm4-common.dtsi:250 */
			renesas,resolution = < 0x10 >;           /* in zephyr/dts/arm/renesas/ra/ra4/ra4-cm4-common.dtsi:251 */
			status = "disabled";                     /* in zephyr/dts/arm/renesas/ra/ra4/ra4-cm4-common.dtsi:252 */

			/* node '/soc/agt@40084100/counter' defined in zephyr/dts/arm/renesas/ra/ra4/ra4-cm4-common.dtsi:254 */
			counter {
				compatible = "renesas,ra-agt-counter"; /* in zephyr/dts/arm/renesas/ra/ra4/ra4-cm4-common.dtsi:255 */
				status = "disabled";                   /* in zephyr/dts/arm/renesas/ra/ra4/ra4-cm4-common.dtsi:256 */
			};
		};

		/* node '/soc/adc@4005c000' defined in zephyr/dts/arm/renesas/ra/ra4/ra4-cm4-common.dtsi:260 */
		adc0: adc@4005c000 {
			compatible = "renesas,ra-adc";          /* in zephyr/dts/arm/renesas/ra/ra4/ra4-cm4-common.dtsi:261 */
			interrupt-names = "scanend";            /* in zephyr/dts/arm/renesas/ra/ra4/ra4-cm4-common.dtsi:262 */
			reg = < 0x4005c000 0x100 >;             /* in zephyr/dts/arm/renesas/ra/ra4/ra4-cm4-common.dtsi:263 */
			#io-channel-cells = < 0x1 >;            /* in zephyr/dts/arm/renesas/ra/ra4/ra4-cm4-common.dtsi:264 */
			vref-mv = < 0xce4 >;                    /* in zephyr/dts/arm/renesas/ra/ra4/ra4-cm4-common.dtsi:265 */
			interrupts = < 0x14 0x1 >;              /* in zephyr/dts/arm/renesas/ra/ra4/r7fa4m1ax.dtsi:72 */
			channel-available-mask = < 0x3ff7fff >; /* in zephyr/dts/arm/renesas/ra/ra4/r7fa4m1ax.dtsi:73 */
			status = "okay";                        /* in zephyr/boards/renesas/ek_ra4m1/ek_ra4m1.dts:102 */
			pinctrl-0 = < &adc0_default >;          /* in zephyr/boards/renesas/ek_ra4m1/ek_ra4m1.dts:103 */
			pinctrl-names = "default";              /* in zephyr/boards/renesas/ek_ra4m1/ek_ra4m1.dts:104 */
		};

		/* node '/soc/dac_global@4005e000' defined in zephyr/dts/arm/renesas/ra/ra4/ra4-cm4-common.dtsi:269 */
		dac_global: dac_global@4005e000 {
			compatible = "renesas,ra-dac-global"; /* in zephyr/dts/arm/renesas/ra/ra4/ra4-cm4-common.dtsi:270 */
			reg = < 0x4005e000 0x10c4 >;          /* in zephyr/dts/arm/renesas/ra/ra4/ra4-cm4-common.dtsi:271 */
			#address-cells = < 0x1 >;             /* in zephyr/dts/arm/renesas/ra/ra4/ra4-cm4-common.dtsi:272 */
			#size-cells = < 0x0 >;                /* in zephyr/dts/arm/renesas/ra/ra4/ra4-cm4-common.dtsi:273 */
			status = "okay";                      /* in zephyr/dts/arm/renesas/ra/ra4/ra4-cm4-common.dtsi:274 */
			has-davrefcr;                         /* in zephyr/dts/arm/renesas/ra/ra4/r7fa4m1ax.dtsi:349 */

			/* node '/soc/dac_global@4005e000/dac@0' defined in zephyr/dts/arm/renesas/ra/ra4/ra4-cm4-common.dtsi:276 */
			dac0: dac@0 {
				compatible = "renesas,ra-dac"; /* in zephyr/dts/arm/renesas/ra/ra4/ra4-cm4-common.dtsi:277 */
				#io-channel-cells = < 0x1 >;   /* in zephyr/dts/arm/renesas/ra/ra4/ra4-cm4-common.dtsi:278 */
				reg = < 0x0 >;                 /* in zephyr/dts/arm/renesas/ra/ra4/ra4-cm4-common.dtsi:279 */
				pinctrl-0 = < &dac0_default >; /* in zephyr/boards/renesas/ek_ra4m1/ek_ra4m1.dts:108 */
				pinctrl-names = "default";     /* in zephyr/boards/renesas/ek_ra4m1/ek_ra4m1.dts:109 */
				status = "okay";               /* in zephyr/boards/renesas/ek_ra4m1/ek_ra4m1.dts:110 */
			};
		};

		/* node '/soc/crc@40074000' defined in zephyr/dts/arm/renesas/ra/ra4/ra4-cm4-common.dtsi:284 */
		crc: crc@40074000 {
			compatible = "renesas,ra-crc"; /* in zephyr/dts/arm/renesas/ra/ra4/ra4-cm4-common.dtsi:285 */
			reg = < 0x40074000 0x1000 >;   /* in zephyr/dts/arm/renesas/ra/ra4/ra4-cm4-common.dtsi:286 */
			clocks = < &pclka 0x2 0x1 >;   /* in zephyr/dts/arm/renesas/ra/ra4/ra4-cm4-common.dtsi:287 */
			status = "okay";               /* in zephyr/boards/renesas/ek_ra4m1/ek_ra4m1.dts:146 */
		};

		/* node '/soc/iic0@40053000' defined in zephyr/dts/arm/renesas/ra/ra4/ra4-cm4-common.dtsi:291 */
		iic0: iic0@40053000 {
			compatible = "renesas,ra-iic"; /* in zephyr/dts/arm/renesas/ra/ra4/ra4-cm4-common.dtsi:292 */
			channel = < 0x0 >;             /* in zephyr/dts/arm/renesas/ra/ra4/ra4-cm4-common.dtsi:293 */
			reg = < 0x40053000 0x100 >;    /* in zephyr/dts/arm/renesas/ra/ra4/ra4-cm4-common.dtsi:294 */
			status = "disabled";           /* in zephyr/dts/arm/renesas/ra/ra4/ra4-cm4-common.dtsi:295 */
		};

		/* node '/soc/iic1@40053100' defined in zephyr/dts/arm/renesas/ra/ra4/ra4-cm4-common.dtsi:298 */
		iic1: iic1@40053100 {
			compatible = "renesas,ra-iic"; /* in zephyr/dts/arm/renesas/ra/ra4/ra4-cm4-common.dtsi:299 */
			channel = < 0x1 >;             /* in zephyr/dts/arm/renesas/ra/ra4/ra4-cm4-common.dtsi:300 */
			reg = < 0x40053100 0x100 >;    /* in zephyr/dts/arm/renesas/ra/ra4/ra4-cm4-common.dtsi:301 */
			pinctrl-0 = < &iic1_default >; /* in zephyr/boards/renesas/ek_ra4m1/ek_ra4m1.dts:131 */
			pinctrl-names = "default";     /* in zephyr/boards/renesas/ek_ra4m1/ek_ra4m1.dts:132 */
			#address-cells = < 0x1 >;      /* in zephyr/boards/renesas/ek_ra4m1/ek_ra4m1.dts:133 */
			#size-cells = < 0x0 >;         /* in zephyr/boards/renesas/ek_ra4m1/ek_ra4m1.dts:134 */
			clock-frequency = < 0xf4240 >; /* in zephyr/boards/renesas/ek_ra4m1/ek_ra4m1.dts:135 */
			interrupts = < 0xa 0x1 >,
			             < 0xb 0x1 >,
			             < 0xc 0x1 >,
			             < 0xd 0x1 >;      /* in zephyr/boards/renesas/ek_ra4m1/ek_ra4m1.dts:136 */
			interrupt-names = "rxi",
			                  "txi",
			                  "tei",
			                  "eri";       /* in zephyr/boards/renesas/ek_ra4m1/ek_ra4m1.dts:137 */
			status = "okay";               /* in zephyr/boards/renesas/ek_ra4m1/ek_ra4m1.dts:138 */
		};

		/* node '/soc/usbfs@40090000' defined in zephyr/dts/arm/renesas/ra/ra4/ra4-cm4-common.dtsi:305 */
		usbfs: usbfs@40090000 {
			compatible = "renesas,ra-usbfs"; /* in zephyr/dts/arm/renesas/ra/ra4/ra4-cm4-common.dtsi:306 */
			reg = < 0x40090000 0x2000 >;     /* in zephyr/dts/arm/renesas/ra/ra4/ra4-cm4-common.dtsi:307 */
			num-bidir-endpoints = < 0xa >;   /* in zephyr/dts/arm/renesas/ra/ra4/ra4-cm4-common.dtsi:308 */
			interrupts = < 0xc 0x1 >,
			             < 0xd 0x1 >;        /* in zephyr/dts/arm/renesas/ra/ra4/ra4-cm4-common.dtsi:309 */
			interrupt-names = "usbfs-i",
			                  "usbfs-r";     /* in zephyr/dts/arm/renesas/ra/ra4/ra4-cm4-common.dtsi:310 */
			phys = < &usbfs_phy >;           /* in zephyr/dts/arm/renesas/ra/ra4/ra4-cm4-common.dtsi:311 */
			phys-clock = < &uclk >;          /* in zephyr/dts/arm/renesas/ra/ra4/ra4-cm4-common.dtsi:312 */
			status = "disabled";             /* in zephyr/dts/arm/renesas/ra/ra4/ra4-cm4-common.dtsi:313 */

			/* node '/soc/usbfs@40090000/udc' defined in zephyr/dts/arm/renesas/ra/ra4/ra4-cm4-common.dtsi:315 */
			udc {
				compatible = "renesas,ra-udc"; /* in zephyr/dts/arm/renesas/ra/ra4/ra4-cm4-common.dtsi:316 */
				status = "disabled";           /* in zephyr/dts/arm/renesas/ra/ra4/ra4-cm4-common.dtsi:317 */
			};
		};

		/* node '/soc/external-interrupt@40006000' defined in zephyr/dts/arm/renesas/ra/ra4/ra4-cm4-common.dtsi:321 */
		port_irq0: external-interrupt@40006000 {
			compatible = "renesas,ra-external-interrupt"; /* in zephyr/dts/arm/renesas/ra/ra4/ra4-cm4-common.dtsi:322 */
			reg = < 0x40006000 0x1 >;                     /* in zephyr/dts/arm/renesas/ra/ra4/ra4-cm4-common.dtsi:323 */
			channel = < 0x0 >;                            /* in zephyr/dts/arm/renesas/ra/ra4/ra4-cm4-common.dtsi:324 */
			renesas,sample-clock-div = < 0x40 >;          /* in zephyr/dts/arm/renesas/ra/ra4/ra4-cm4-common.dtsi:325 */
			#port-irq-cells = < 0x0 >;                    /* in zephyr/dts/arm/renesas/ra/ra4/ra4-cm4-common.dtsi:326 */
			interrupts = < 0x1b 0xc >;                    /* in zephyr/boards/renesas/ek_ra4m1/ek_ra4m1.dts:114 */
			status = "okay";                              /* in zephyr/boards/renesas/ek_ra4m1/ek_ra4m1.dts:115 */
			phandle = < 0xa >;                            /* in zephyr/dts/arm/renesas/ra/ra4/r7fa4m1ax.dtsi:270 */
		};

		/* node '/soc/external-interrupt@40006001' defined in zephyr/dts/arm/renesas/ra/ra4/ra4-cm4-common.dtsi:330 */
		port_irq1: external-interrupt@40006001 {
			compatible = "renesas,ra-external-interrupt"; /* in zephyr/dts/arm/renesas/ra/ra4/ra4-cm4-common.dtsi:331 */
			reg = < 0x40006001 0x1 >;                     /* in zephyr/dts/arm/renesas/ra/ra4/ra4-cm4-common.dtsi:332 */
			channel = < 0x1 >;                            /* in zephyr/dts/arm/renesas/ra/ra4/ra4-cm4-common.dtsi:333 */
			renesas,sample-clock-div = < 0x40 >;          /* in zephyr/dts/arm/renesas/ra/ra4/ra4-cm4-common.dtsi:334 */
			#port-irq-cells = < 0x0 >;                    /* in zephyr/dts/arm/renesas/ra/ra4/ra4-cm4-common.dtsi:335 */
			status = "disabled";                          /* in zephyr/dts/arm/renesas/ra/ra4/ra4-cm4-common.dtsi:336 */
			phandle = < 0xb >;                            /* in zephyr/dts/arm/renesas/ra/ra4/r7fa4m1ax.dtsi:270 */
		};

		/* node '/soc/external-interrupt@40006002' defined in zephyr/dts/arm/renesas/ra/ra4/ra4-cm4-common.dtsi:339 */
		port_irq2: external-interrupt@40006002 {
			compatible = "renesas,ra-external-interrupt"; /* in zephyr/dts/arm/renesas/ra/ra4/ra4-cm4-common.dtsi:340 */
			reg = < 0x40006002 0x1 >;                     /* in zephyr/dts/arm/renesas/ra/ra4/ra4-cm4-common.dtsi:341 */
			channel = < 0x2 >;                            /* in zephyr/dts/arm/renesas/ra/ra4/ra4-cm4-common.dtsi:342 */
			renesas,sample-clock-div = < 0x40 >;          /* in zephyr/dts/arm/renesas/ra/ra4/ra4-cm4-common.dtsi:343 */
			#port-irq-cells = < 0x0 >;                    /* in zephyr/dts/arm/renesas/ra/ra4/ra4-cm4-common.dtsi:344 */
			status = "disabled";                          /* in zephyr/dts/arm/renesas/ra/ra4/ra4-cm4-common.dtsi:345 */
			phandle = < 0x4 >;                            /* in zephyr/dts/arm/renesas/ra/ra4/r7fa4m1ax.dtsi:253 */
		};

		/* node '/soc/external-interrupt@40006003' defined in zephyr/dts/arm/renesas/ra/ra4/ra4-cm4-common.dtsi:348 */
		port_irq3: external-interrupt@40006003 {
			compatible = "renesas,ra-external-interrupt"; /* in zephyr/dts/arm/renesas/ra/ra4/ra4-cm4-common.dtsi:349 */
			reg = < 0x40006003 0x1 >;                     /* in zephyr/dts/arm/renesas/ra/ra4/ra4-cm4-common.dtsi:350 */
			channel = < 0x3 >;                            /* in zephyr/dts/arm/renesas/ra/ra4/ra4-cm4-common.dtsi:351 */
			renesas,sample-clock-div = < 0x40 >;          /* in zephyr/dts/arm/renesas/ra/ra4/ra4-cm4-common.dtsi:352 */
			#port-irq-cells = < 0x0 >;                    /* in zephyr/dts/arm/renesas/ra/ra4/ra4-cm4-common.dtsi:353 */
			status = "disabled";                          /* in zephyr/dts/arm/renesas/ra/ra4/ra4-cm4-common.dtsi:354 */
			phandle = < 0x5 >;                            /* in zephyr/dts/arm/renesas/ra/ra4/r7fa4m1ax.dtsi:253 */
		};

		/* node '/soc/external-interrupt@40006004' defined in zephyr/dts/arm/renesas/ra/ra4/ra4-cm4-common.dtsi:357 */
		port_irq4: external-interrupt@40006004 {
			compatible = "renesas,ra-external-interrupt"; /* in zephyr/dts/arm/renesas/ra/ra4/ra4-cm4-common.dtsi:358 */
			reg = < 0x40006004 0x1 >;                     /* in zephyr/dts/arm/renesas/ra/ra4/ra4-cm4-common.dtsi:359 */
			channel = < 0x4 >;                            /* in zephyr/dts/arm/renesas/ra/ra4/ra4-cm4-common.dtsi:360 */
			renesas,sample-clock-div = < 0x40 >;          /* in zephyr/dts/arm/renesas/ra/ra4/ra4-cm4-common.dtsi:361 */
			#port-irq-cells = < 0x0 >;                    /* in zephyr/dts/arm/renesas/ra/ra4/ra4-cm4-common.dtsi:362 */
			status = "disabled";                          /* in zephyr/dts/arm/renesas/ra/ra4/ra4-cm4-common.dtsi:363 */
			phandle = < 0xc >;                            /* in zephyr/dts/arm/renesas/ra/ra4/r7fa4m1ax.dtsi:270 */
		};

		/* node '/soc/external-interrupt@40006006' defined in zephyr/dts/arm/renesas/ra/ra4/ra4-cm4-common.dtsi:366 */
		port_irq6: external-interrupt@40006006 {
			compatible = "renesas,ra-external-interrupt"; /* in zephyr/dts/arm/renesas/ra/ra4/ra4-cm4-common.dtsi:367 */
			reg = < 0x40006006 0x1 >;                     /* in zephyr/dts/arm/renesas/ra/ra4/ra4-cm4-common.dtsi:368 */
			channel = < 0x6 >;                            /* in zephyr/dts/arm/renesas/ra/ra4/ra4-cm4-common.dtsi:369 */
			renesas,sample-clock-div = < 0x40 >;          /* in zephyr/dts/arm/renesas/ra/ra4/ra4-cm4-common.dtsi:370 */
			#port-irq-cells = < 0x0 >;                    /* in zephyr/dts/arm/renesas/ra/ra4/ra4-cm4-common.dtsi:371 */
			status = "disabled";                          /* in zephyr/dts/arm/renesas/ra/ra4/ra4-cm4-common.dtsi:372 */
			phandle = < 0x6 >;                            /* in zephyr/dts/arm/renesas/ra/ra4/r7fa4m1ax.dtsi:253 */
		};

		/* node '/soc/external-interrupt@40006007' defined in zephyr/dts/arm/renesas/ra/ra4/ra4-cm4-common.dtsi:375 */
		port_irq7: external-interrupt@40006007 {
			compatible = "renesas,ra-external-interrupt"; /* in zephyr/dts/arm/renesas/ra/ra4/ra4-cm4-common.dtsi:376 */
			reg = < 0x40006007 0x1 >;                     /* in zephyr/dts/arm/renesas/ra/ra4/ra4-cm4-common.dtsi:377 */
			channel = < 0x7 >;                            /* in zephyr/dts/arm/renesas/ra/ra4/ra4-cm4-common.dtsi:378 */
			renesas,sample-clock-div = < 0x40 >;          /* in zephyr/dts/arm/renesas/ra/ra4/ra4-cm4-common.dtsi:379 */
			#port-irq-cells = < 0x0 >;                    /* in zephyr/dts/arm/renesas/ra/ra4/ra4-cm4-common.dtsi:380 */
			status = "disabled";                          /* in zephyr/dts/arm/renesas/ra/ra4/ra4-cm4-common.dtsi:381 */
			phandle = < 0x7 >;                            /* in zephyr/dts/arm/renesas/ra/ra4/r7fa4m1ax.dtsi:253 */
		};

		/* node '/soc/external-interrupt@40006009' defined in zephyr/dts/arm/renesas/ra/ra4/ra4-cm4-common.dtsi:384 */
		port_irq9: external-interrupt@40006009 {
			compatible = "renesas,ra-external-interrupt"; /* in zephyr/dts/arm/renesas/ra/ra4/ra4-cm4-common.dtsi:385 */
			reg = < 0x40006009 0x1 >;                     /* in zephyr/dts/arm/renesas/ra/ra4/ra4-cm4-common.dtsi:386 */
			channel = < 0x9 >;                            /* in zephyr/dts/arm/renesas/ra/ra4/ra4-cm4-common.dtsi:387 */
			renesas,sample-clock-div = < 0x40 >;          /* in zephyr/dts/arm/renesas/ra/ra4/ra4-cm4-common.dtsi:388 */
			#port-irq-cells = < 0x0 >;                    /* in zephyr/dts/arm/renesas/ra/ra4/ra4-cm4-common.dtsi:389 */
			status = "disabled";                          /* in zephyr/dts/arm/renesas/ra/ra4/ra4-cm4-common.dtsi:390 */
			phandle = < 0xf >;                            /* in zephyr/dts/arm/renesas/ra/ra4/r7fa4m1ax.dtsi:298 */
		};

		/* node '/soc/external-interrupt@4000600b' defined in zephyr/dts/arm/renesas/ra/ra4/ra4-cm4-common.dtsi:393 */
		port_irq11: external-interrupt@4000600b {
			compatible = "renesas,ra-external-interrupt"; /* in zephyr/dts/arm/renesas/ra/ra4/ra4-cm4-common.dtsi:394 */
			reg = < 0x4000600b 0x1 >;                     /* in zephyr/dts/arm/renesas/ra/ra4/ra4-cm4-common.dtsi:395 */
			channel = < 0xb >;                            /* in zephyr/dts/arm/renesas/ra/ra4/ra4-cm4-common.dtsi:396 */
			renesas,sample-clock-div = < 0x40 >;          /* in zephyr/dts/arm/renesas/ra/ra4/ra4-cm4-common.dtsi:397 */
			#port-irq-cells = < 0x0 >;                    /* in zephyr/dts/arm/renesas/ra/ra4/ra4-cm4-common.dtsi:398 */
			status = "disabled";                          /* in zephyr/dts/arm/renesas/ra/ra4/ra4-cm4-common.dtsi:399 */
			phandle = < 0x10 >;                           /* in zephyr/dts/arm/renesas/ra/ra4/r7fa4m1ax.dtsi:331 */
		};

		/* node '/soc/external-interrupt@4000600e' defined in zephyr/dts/arm/renesas/ra/ra4/ra4-cm4-common.dtsi:402 */
		port_irq14: external-interrupt@4000600e {
			compatible = "renesas,ra-external-interrupt"; /* in zephyr/dts/arm/renesas/ra/ra4/ra4-cm4-common.dtsi:403 */
			reg = < 0x4000600e 0x1 >;                     /* in zephyr/dts/arm/renesas/ra/ra4/ra4-cm4-common.dtsi:404 */
			channel = < 0xe >;                            /* in zephyr/dts/arm/renesas/ra/ra4/ra4-cm4-common.dtsi:405 */
			renesas,sample-clock-div = < 0x40 >;          /* in zephyr/dts/arm/renesas/ra/ra4/ra4-cm4-common.dtsi:406 */
			#port-irq-cells = < 0x0 >;                    /* in zephyr/dts/arm/renesas/ra/ra4/ra4-cm4-common.dtsi:407 */
			status = "disabled";                          /* in zephyr/dts/arm/renesas/ra/ra4/ra4-cm4-common.dtsi:408 */
			phandle = < 0x12 >;                           /* in zephyr/dts/arm/renesas/ra/ra4/r7fa4m1ax.dtsi:331 */
		};

		/* node '/soc/external-interrupt@4000600f' defined in zephyr/dts/arm/renesas/ra/ra4/ra4-cm4-common.dtsi:411 */
		port_irq15: external-interrupt@4000600f {
			compatible = "renesas,ra-external-interrupt"; /* in zephyr/dts/arm/renesas/ra/ra4/ra4-cm4-common.dtsi:412 */
			reg = < 0x4000600f 0x1 >;                     /* in zephyr/dts/arm/renesas/ra/ra4/ra4-cm4-common.dtsi:413 */
			channel = < 0xf >;                            /* in zephyr/dts/arm/renesas/ra/ra4/ra4-cm4-common.dtsi:414 */
			renesas,sample-clock-div = < 0x40 >;          /* in zephyr/dts/arm/renesas/ra/ra4/ra4-cm4-common.dtsi:415 */
			#port-irq-cells = < 0x0 >;                    /* in zephyr/dts/arm/renesas/ra/ra4/ra4-cm4-common.dtsi:416 */
			status = "disabled";                          /* in zephyr/dts/arm/renesas/ra/ra4/ra4-cm4-common.dtsi:417 */
			phandle = < 0x9 >;                            /* in zephyr/dts/arm/renesas/ra/ra4/r7fa4m1ax.dtsi:253 */
		};

		/* node '/soc/pwm0@40078000' defined in zephyr/dts/arm/renesas/ra/ra4/ra4-cm4-common.dtsi:420 */
		pwm0: pwm0@40078000 {
			compatible = "renesas,ra-pwm"; /* in zephyr/dts/arm/renesas/ra/ra4/ra4-cm4-common.dtsi:421 */
			divider = < 0x0 >;             /* in zephyr/dts/arm/renesas/ra/ra4/ra4-cm4-common.dtsi:422 */
			channel = < 0x0 >;             /* in zephyr/dts/arm/renesas/ra/ra4/ra4-cm4-common.dtsi:423 */
			clocks = < &pclkd 0x3 0x5 >;   /* in zephyr/dts/arm/renesas/ra/ra4/ra4-cm4-common.dtsi:424 */
			reg = < 0x40078000 0x100 >;    /* in zephyr/dts/arm/renesas/ra/ra4/ra4-cm4-common.dtsi:425 */
			#pwm-cells = < 0x3 >;          /* in zephyr/dts/arm/renesas/ra/ra4/ra4-cm4-common.dtsi:426 */
			status = "disabled";           /* in zephyr/dts/arm/renesas/ra/ra4/ra4-cm4-common.dtsi:427 */
		};

		/* node '/soc/pwm1@40078100' defined in zephyr/dts/arm/renesas/ra/ra4/ra4-cm4-common.dtsi:430 */
		pwm1: pwm1@40078100 {
			compatible = "renesas,ra-pwm"; /* in zephyr/dts/arm/renesas/ra/ra4/ra4-cm4-common.dtsi:431 */
			divider = < 0x0 >;             /* in zephyr/dts/arm/renesas/ra/ra4/ra4-cm4-common.dtsi:432 */
			channel = < 0x1 >;             /* in zephyr/dts/arm/renesas/ra/ra4/ra4-cm4-common.dtsi:433 */
			clocks = < &pclkd 0x3 0x5 >;   /* in zephyr/dts/arm/renesas/ra/ra4/ra4-cm4-common.dtsi:434 */
			reg = < 0x40078100 0x100 >;    /* in zephyr/dts/arm/renesas/ra/ra4/ra4-cm4-common.dtsi:435 */
			#pwm-cells = < 0x3 >;          /* in zephyr/dts/arm/renesas/ra/ra4/ra4-cm4-common.dtsi:436 */
			pinctrl-0 = < &pwm1_default >; /* in zephyr/boards/renesas/ek_ra4m1/ek_ra4m1.dts:123 */
			pinctrl-names = "default";     /* in zephyr/boards/renesas/ek_ra4m1/ek_ra4m1.dts:124 */
			interrupts = < 0x8 0x1 >,
			             < 0x9 0x1 >;      /* in zephyr/boards/renesas/ek_ra4m1/ek_ra4m1.dts:125 */
			interrupt-names = "gtioca",
			                  "overflow";  /* in zephyr/boards/renesas/ek_ra4m1/ek_ra4m1.dts:126 */
			status = "okay";               /* in zephyr/boards/renesas/ek_ra4m1/ek_ra4m1.dts:127 */
		};

		/* node '/soc/pwm2@40078200' defined in zephyr/dts/arm/renesas/ra/ra4/ra4-cm4-common.dtsi:440 */
		pwm2: pwm2@40078200 {
			compatible = "renesas,ra-pwm"; /* in zephyr/dts/arm/renesas/ra/ra4/ra4-cm4-common.dtsi:441 */
			divider = < 0x0 >;             /* in zephyr/dts/arm/renesas/ra/ra4/ra4-cm4-common.dtsi:442 */
			channel = < 0x2 >;             /* in zephyr/dts/arm/renesas/ra/ra4/ra4-cm4-common.dtsi:443 */
			reg = < 0x40078200 0x100 >;    /* in zephyr/dts/arm/renesas/ra/ra4/ra4-cm4-common.dtsi:444 */
			#pwm-cells = < 0x3 >;          /* in zephyr/dts/arm/renesas/ra/ra4/ra4-cm4-common.dtsi:445 */
			status = "disabled";           /* in zephyr/dts/arm/renesas/ra/ra4/ra4-cm4-common.dtsi:446 */
			clocks = < &pclkd 0x3 0x6 >;   /* in zephyr/dts/arm/renesas/ra/ra4/r7fa4m1ax.dtsi:341 */
		};

		/* node '/soc/pwm3@40078300' defined in zephyr/dts/arm/renesas/ra/ra4/ra4-cm4-common.dtsi:449 */
		pwm3: pwm3@40078300 {
			compatible = "renesas,ra-pwm"; /* in zephyr/dts/arm/renesas/ra/ra4/ra4-cm4-common.dtsi:450 */
			divider = < 0x0 >;             /* in zephyr/dts/arm/renesas/ra/ra4/ra4-cm4-common.dtsi:451 */
			channel = < 0x3 >;             /* in zephyr/dts/arm/renesas/ra/ra4/ra4-cm4-common.dtsi:452 */
			reg = < 0x40078300 0x100 >;    /* in zephyr/dts/arm/renesas/ra/ra4/ra4-cm4-common.dtsi:453 */
			#pwm-cells = < 0x3 >;          /* in zephyr/dts/arm/renesas/ra/ra4/ra4-cm4-common.dtsi:454 */
			status = "disabled";           /* in zephyr/dts/arm/renesas/ra/ra4/ra4-cm4-common.dtsi:455 */
			clocks = < &pclkd 0x3 0x6 >;   /* in zephyr/dts/arm/renesas/ra/ra4/r7fa4m1ax.dtsi:345 */
		};

		/* node '/soc/pwm4@40078400' defined in zephyr/dts/arm/renesas/ra/ra4/ra4-cm4-common.dtsi:458 */
		pwm4: pwm4@40078400 {
			compatible = "renesas,ra-pwm"; /* in zephyr/dts/arm/renesas/ra/ra4/ra4-cm4-common.dtsi:459 */
			divider = < 0x0 >;             /* in zephyr/dts/arm/renesas/ra/ra4/ra4-cm4-common.dtsi:460 */
			channel = < 0x4 >;             /* in zephyr/dts/arm/renesas/ra/ra4/ra4-cm4-common.dtsi:461 */
			clocks = < &pclkd 0x3 0x6 >;   /* in zephyr/dts/arm/renesas/ra/ra4/ra4-cm4-common.dtsi:462 */
			reg = < 0x40078400 0x100 >;    /* in zephyr/dts/arm/renesas/ra/ra4/ra4-cm4-common.dtsi:463 */
			#pwm-cells = < 0x3 >;          /* in zephyr/dts/arm/renesas/ra/ra4/ra4-cm4-common.dtsi:464 */
			status = "disabled";           /* in zephyr/dts/arm/renesas/ra/ra4/ra4-cm4-common.dtsi:465 */
		};

		/* node '/soc/pwm5@40078500' defined in zephyr/dts/arm/renesas/ra/ra4/ra4-cm4-common.dtsi:468 */
		pwm5: pwm5@40078500 {
			compatible = "renesas,ra-pwm"; /* in zephyr/dts/arm/renesas/ra/ra4/ra4-cm4-common.dtsi:469 */
			divider = < 0x0 >;             /* in zephyr/dts/arm/renesas/ra/ra4/ra4-cm4-common.dtsi:470 */
			channel = < 0x5 >;             /* in zephyr/dts/arm/renesas/ra/ra4/ra4-cm4-common.dtsi:471 */
			clocks = < &pclkd 0x3 0x6 >;   /* in zephyr/dts/arm/renesas/ra/ra4/ra4-cm4-common.dtsi:472 */
			reg = < 0x40078500 0x100 >;    /* in zephyr/dts/arm/renesas/ra/ra4/ra4-cm4-common.dtsi:473 */
			#pwm-cells = < 0x3 >;          /* in zephyr/dts/arm/renesas/ra/ra4/ra4-cm4-common.dtsi:474 */
			status = "disabled";           /* in zephyr/dts/arm/renesas/ra/ra4/ra4-cm4-common.dtsi:475 */
		};

		/* node '/soc/wdt@40044200' defined in zephyr/dts/arm/renesas/ra/ra4/ra4-cm4-common.dtsi:478 */
		wdt: wdt@40044200 {
			compatible = "renesas,ra-wdt"; /* in zephyr/dts/arm/renesas/ra/ra4/ra4-cm4-common.dtsi:479 */
			reg = < 0x40044200 0x200 >;    /* in zephyr/dts/arm/renesas/ra/ra4/ra4-cm4-common.dtsi:480 */
			clocks = < &pclkb 0x0 0x0 >;   /* in zephyr/dts/arm/renesas/ra/ra4/ra4-cm4-common.dtsi:481 */
			status = "okay";               /* in zephyr/boards/renesas/ek_ra4m1/ek_ra4m1.dts:142 */
		};

		/* node '/soc/ctsua@40081000' defined in zephyr/dts/arm/renesas/ra/ra4/ra4-cm4-common.dtsi:485 */
		ctsu: ctsua@40081000 {
			compatible = "renesas,ra-ctsu"; /* in zephyr/dts/arm/renesas/ra/ra4/ra4-cm4-common.dtsi:486 */
			reg = < 0x40081000 0x24 >;      /* in zephyr/dts/arm/renesas/ra/ra4/ra4-cm4-common.dtsi:487 */
			clocks = < &pclkb 0x2 0x3 >;    /* in zephyr/dts/arm/renesas/ra/ra4/ra4-cm4-common.dtsi:488 */
			variant = "ctsua";              /* in zephyr/dts/arm/renesas/ra/ra4/ra4-cm4-common.dtsi:489 */
			status = "disabled";            /* in zephyr/dts/arm/renesas/ra/ra4/ra4-cm4-common.dtsi:490 */
		};

		/* node '/soc/option-setting-ofs0@400' defined in zephyr/dts/arm/renesas/ra/ra4/ra4-cm4-common.dtsi:493 */
		option_setting_ofs0: option-setting-ofs0@400 {
			compatible = "renesas,ofs-memory"; /* in zephyr/dts/arm/renesas/ra/ra4/ra4-cm4-common.dtsi:494 */
			reg = < 0x400 0x4 >;               /* in zephyr/dts/arm/renesas/ra/ra4/ra4-cm4-common.dtsi:495 */
			status = "okay";                   /* in zephyr/dts/arm/renesas/ra/ra4/ra4-cm4-common.dtsi:496 */
		};

		/* node '/soc/option-setting-ofs1@404' defined in zephyr/dts/arm/renesas/ra/ra4/ra4-cm4-common.dtsi:499 */
		option_setting_ofs1: option-setting-ofs1@404 {
			compatible = "renesas,ofs-memory"; /* in zephyr/dts/arm/renesas/ra/ra4/ra4-cm4-common.dtsi:500 */
			reg = < 0x404 0x4 >;               /* in zephyr/dts/arm/renesas/ra/ra4/ra4-cm4-common.dtsi:501 */
			status = "okay";                   /* in zephyr/dts/arm/renesas/ra/ra4/ra4-cm4-common.dtsi:502 */
		};

		/* node '/soc/option-setting-secmpu@408' defined in zephyr/dts/arm/renesas/ra/ra4/ra4-cm4-common.dtsi:505 */
		option_setting_secmpu: option-setting-secmpu@408 {
			compatible = "renesas,ofs-memory"; /* in zephyr/dts/arm/renesas/ra/ra4/ra4-cm4-common.dtsi:506 */
			reg = < 0x408 0x34 >;              /* in zephyr/dts/arm/renesas/ra/ra4/ra4-cm4-common.dtsi:507 */
			status = "okay";                   /* in zephyr/dts/arm/renesas/ra/ra4/ra4-cm4-common.dtsi:508 */
		};

		/* node '/soc/option-setting-osis@1010018' defined in zephyr/dts/arm/renesas/ra/ra4/ra4-cm4-common.dtsi:511 */
		option_setting_osis: option-setting-osis@1010018 {
			compatible = "zephyr,memory-region";      /* in zephyr/dts/arm/renesas/ra/ra4/ra4-cm4-common.dtsi:512 */
			zephyr,memory-region = "OFS_OSIS_MEMORY"; /* in zephyr/dts/arm/renesas/ra/ra4/ra4-cm4-common.dtsi:513 */
			reg = < 0x1010018 0x1c >;                 /* in zephyr/dts/arm/renesas/ra/ra4/ra4-cm4-common.dtsi:514 */
			status = "okay";                          /* in zephyr/dts/arm/renesas/ra/ra4/ra4-cm4-common.dtsi:515 */
		};

		/* node '/soc/memory@20000000' defined in zephyr/dts/arm/renesas/ra/ra4/r7fa4m1ax.dtsi:13 */
		sram0: memory@20000000 {
			compatible = "mmio-sram";    /* in zephyr/dts/arm/renesas/ra/ra4/r7fa4m1ax.dtsi:14 */
			reg = < 0x20000000 0x8000 >; /* in zephyr/dts/arm/renesas/ra/ra4/r7fa4m1ax.dtsi:15 */
		};

		/* node '/soc/gpio@400400c0' defined in zephyr/dts/arm/renesas/ra/ra4/r7fa4m1ax.dtsi:18 */
		ioport6: gpio@400400c0 {
			compatible = "renesas,ra-gpio-ioport"; /* in zephyr/dts/arm/renesas/ra/ra4/r7fa4m1ax.dtsi:19 */
			reg = < 0x400400c0 0x20 >;             /* in zephyr/dts/arm/renesas/ra/ra4/r7fa4m1ax.dtsi:20 */
			port = < 0x6 >;                        /* in zephyr/dts/arm/renesas/ra/ra4/r7fa4m1ax.dtsi:21 */
			gpio-controller;                       /* in zephyr/dts/arm/renesas/ra/ra4/r7fa4m1ax.dtsi:22 */
			#gpio-cells = < 0x2 >;                 /* in zephyr/dts/arm/renesas/ra/ra4/r7fa4m1ax.dtsi:23 */
			ngpios = < 0x10 >;                     /* in zephyr/dts/arm/renesas/ra/ra4/r7fa4m1ax.dtsi:24 */
			status = "disabled";                   /* in zephyr/dts/arm/renesas/ra/ra4/r7fa4m1ax.dtsi:25 */
		};

		/* node '/soc/gpio@400400e0' defined in zephyr/dts/arm/renesas/ra/ra4/r7fa4m1ax.dtsi:28 */
		ioport7: gpio@400400e0 {
			compatible = "renesas,ra-gpio-ioport"; /* in zephyr/dts/arm/renesas/ra/ra4/r7fa4m1ax.dtsi:29 */
			reg = < 0x400400e0 0x20 >;             /* in zephyr/dts/arm/renesas/ra/ra4/r7fa4m1ax.dtsi:30 */
			port = < 0x7 >;                        /* in zephyr/dts/arm/renesas/ra/ra4/r7fa4m1ax.dtsi:31 */
			gpio-controller;                       /* in zephyr/dts/arm/renesas/ra/ra4/r7fa4m1ax.dtsi:32 */
			#gpio-cells = < 0x2 >;                 /* in zephyr/dts/arm/renesas/ra/ra4/r7fa4m1ax.dtsi:33 */
			ngpios = < 0x10 >;                     /* in zephyr/dts/arm/renesas/ra/ra4/r7fa4m1ax.dtsi:34 */
			status = "disabled";                   /* in zephyr/dts/arm/renesas/ra/ra4/r7fa4m1ax.dtsi:35 */
		};

		/* node '/soc/gpio@40040100' defined in zephyr/dts/arm/renesas/ra/ra4/r7fa4m1ax.dtsi:38 */
		ioport8: gpio@40040100 {
			compatible = "renesas,ra-gpio-ioport"; /* in zephyr/dts/arm/renesas/ra/ra4/r7fa4m1ax.dtsi:39 */
			reg = < 0x40040100 0x20 >;             /* in zephyr/dts/arm/renesas/ra/ra4/r7fa4m1ax.dtsi:40 */
			port = < 0x8 >;                        /* in zephyr/dts/arm/renesas/ra/ra4/r7fa4m1ax.dtsi:41 */
			gpio-controller;                       /* in zephyr/dts/arm/renesas/ra/ra4/r7fa4m1ax.dtsi:42 */
			#gpio-cells = < 0x2 >;                 /* in zephyr/dts/arm/renesas/ra/ra4/r7fa4m1ax.dtsi:43 */
			ngpios = < 0x10 >;                     /* in zephyr/dts/arm/renesas/ra/ra4/r7fa4m1ax.dtsi:44 */
			status = "disabled";                   /* in zephyr/dts/arm/renesas/ra/ra4/r7fa4m1ax.dtsi:45 */
		};

		/* node '/soc/sci2@40070040' defined in zephyr/dts/arm/renesas/ra/ra4/r7fa4m1ax.dtsi:48 */
		sci2: sci2@40070040 {
			compatible = "renesas,ra-sci"; /* in zephyr/dts/arm/renesas/ra/ra4/r7fa4m1ax.dtsi:49 */
			reg = < 0x40070040 0x20 >;     /* in zephyr/dts/arm/renesas/ra/ra4/r7fa4m1ax.dtsi:50 */
			interrupts = < 0x8 0x1 >,
			             < 0x9 0x1 >,
			             < 0xa 0x1 >,
			             < 0xb 0x1 >;      /* in zephyr/dts/arm/renesas/ra/ra4/r7fa4m1ax.dtsi:51 */
			interrupt-names = "rxi",
			                  "txi",
			                  "tei",
			                  "eri";       /* in zephyr/dts/arm/renesas/ra/ra4/r7fa4m1ax.dtsi:52 */
			clocks = < &pclka 0x1 0x1d >;  /* in zephyr/dts/arm/renesas/ra/ra4/r7fa4m1ax.dtsi:53 */
			status = "disabled";           /* in zephyr/dts/arm/renesas/ra/ra4/r7fa4m1ax.dtsi:54 */

			/* node '/soc/sci2@40070040/uart' defined in zephyr/dts/arm/renesas/ra/ra4/r7fa4m1ax.dtsi:56 */
			uart {
				compatible = "renesas,ra-sci-uart"; /* in zephyr/dts/arm/renesas/ra/ra4/r7fa4m1ax.dtsi:57 */
				channel = < 0x2 >;                  /* in zephyr/dts/arm/renesas/ra/ra4/r7fa4m1ax.dtsi:58 */
				status = "disabled";                /* in zephyr/dts/arm/renesas/ra/ra4/r7fa4m1ax.dtsi:59 */
			};

			/* node '/soc/sci2@40070040/i2c' defined in zephyr/dts/arm/renesas/ra/ra4/r7fa4m1ax.dtsi:62 */
			i2c {
				compatible = "renesas,ra-i2c-sci"; /* in zephyr/dts/arm/renesas/ra/ra4/r7fa4m1ax.dtsi:63 */
				#address-cells = < 0x1 >;          /* in zephyr/dts/arm/renesas/ra/ra4/r7fa4m1ax.dtsi:64 */
				#size-cells = < 0x0 >;             /* in zephyr/dts/arm/renesas/ra/ra4/r7fa4m1ax.dtsi:65 */
				channel = < 0x2 >;                 /* in zephyr/dts/arm/renesas/ra/ra4/r7fa4m1ax.dtsi:66 */
				status = "disabled";               /* in zephyr/dts/arm/renesas/ra/ra4/r7fa4m1ax.dtsi:67 */
			};
		};

		/* node '/soc/external-interrupt@40006005' defined in zephyr/dts/arm/renesas/ra/ra4/r7fa4m1ax.dtsi:76 */
		port_irq5: external-interrupt@40006005 {
			compatible = "renesas,ra-external-interrupt"; /* in zephyr/dts/arm/renesas/ra/ra4/r7fa4m1ax.dtsi:77 */
			reg = < 0x40006005 0x1 >;                     /* in zephyr/dts/arm/renesas/ra/ra4/r7fa4m1ax.dtsi:78 */
			channel = < 0x5 >;                            /* in zephyr/dts/arm/renesas/ra/ra4/r7fa4m1ax.dtsi:79 */
			renesas,sample-clock-div = < 0x40 >;          /* in zephyr/dts/arm/renesas/ra/ra4/r7fa4m1ax.dtsi:80 */
			#port-irq-cells = < 0x0 >;                    /* in zephyr/dts/arm/renesas/ra/ra4/r7fa4m1ax.dtsi:81 */
			status = "disabled";                          /* in zephyr/dts/arm/renesas/ra/ra4/r7fa4m1ax.dtsi:82 */
			phandle = < 0xd >;                            /* in zephyr/dts/arm/renesas/ra/ra4/r7fa4m1ax.dtsi:298 */
		};

		/* node '/soc/external-interrupt@40006008' defined in zephyr/dts/arm/renesas/ra/ra4/r7fa4m1ax.dtsi:85 */
		port_irq8: external-interrupt@40006008 {
			compatible = "renesas,ra-external-interrupt"; /* in zephyr/dts/arm/renesas/ra/ra4/r7fa4m1ax.dtsi:86 */
			reg = < 0x40006008 0x1 >;                     /* in zephyr/dts/arm/renesas/ra/ra4/r7fa4m1ax.dtsi:87 */
			channel = < 0x8 >;                            /* in zephyr/dts/arm/renesas/ra/ra4/r7fa4m1ax.dtsi:88 */
			renesas,sample-clock-div = < 0x40 >;          /* in zephyr/dts/arm/renesas/ra/ra4/r7fa4m1ax.dtsi:89 */
			#port-irq-cells = < 0x0 >;                    /* in zephyr/dts/arm/renesas/ra/ra4/r7fa4m1ax.dtsi:90 */
			status = "disabled";                          /* in zephyr/dts/arm/renesas/ra/ra4/r7fa4m1ax.dtsi:91 */
			phandle = < 0xe >;                            /* in zephyr/dts/arm/renesas/ra/ra4/r7fa4m1ax.dtsi:298 */
		};

		/* node '/soc/external-interrupt@4000600a' defined in zephyr/dts/arm/renesas/ra/ra4/r7fa4m1ax.dtsi:94 */
		port_irq10: external-interrupt@4000600a {
			compatible = "renesas,ra-external-interrupt"; /* in zephyr/dts/arm/renesas/ra/ra4/r7fa4m1ax.dtsi:95 */
			reg = < 0x4000600a 0x1 >;                     /* in zephyr/dts/arm/renesas/ra/ra4/r7fa4m1ax.dtsi:96 */
			channel = < 0xa >;                            /* in zephyr/dts/arm/renesas/ra/ra4/r7fa4m1ax.dtsi:97 */
			renesas,sample-clock-div = < 0x40 >;          /* in zephyr/dts/arm/renesas/ra/ra4/r7fa4m1ax.dtsi:98 */
			#port-irq-cells = < 0x0 >;                    /* in zephyr/dts/arm/renesas/ra/ra4/r7fa4m1ax.dtsi:99 */
			status = "disabled";                          /* in zephyr/dts/arm/renesas/ra/ra4/r7fa4m1ax.dtsi:100 */
			phandle = < 0x8 >;                            /* in zephyr/dts/arm/renesas/ra/ra4/r7fa4m1ax.dtsi:253 */
		};

		/* node '/soc/external-interrupt@4000600c' defined in zephyr/dts/arm/renesas/ra/ra4/r7fa4m1ax.dtsi:103 */
		port_irq12: external-interrupt@4000600c {
			compatible = "renesas,ra-external-interrupt"; /* in zephyr/dts/arm/renesas/ra/ra4/r7fa4m1ax.dtsi:104 */
			reg = < 0x4000600c 0x1 >;                     /* in zephyr/dts/arm/renesas/ra/ra4/r7fa4m1ax.dtsi:105 */
			channel = < 0xc >;                            /* in zephyr/dts/arm/renesas/ra/ra4/r7fa4m1ax.dtsi:106 */
			renesas,sample-clock-div = < 0x40 >;          /* in zephyr/dts/arm/renesas/ra/ra4/r7fa4m1ax.dtsi:107 */
			#port-irq-cells = < 0x0 >;                    /* in zephyr/dts/arm/renesas/ra/ra4/r7fa4m1ax.dtsi:108 */
			status = "disabled";                          /* in zephyr/dts/arm/renesas/ra/ra4/r7fa4m1ax.dtsi:109 */
			phandle = < 0x11 >;                           /* in zephyr/dts/arm/renesas/ra/ra4/r7fa4m1ax.dtsi:331 */
		};

		/* node '/soc/trng' defined in zephyr/dts/arm/renesas/ra/ra4/r7fa4m1ax.dtsi:112 */
		trng: trng {
			compatible = "renesas,ra-sce5-rng"; /* in zephyr/dts/arm/renesas/ra/ra4/r7fa4m1ax.dtsi:113 */
			status = "okay";                    /* in zephyr/boards/renesas/ek_ra4m1/ek_ra4m1.dts:119 */
		};

		/* node '/soc/pwm6@40078600' defined in zephyr/dts/arm/renesas/ra/ra4/r7fa4m1ax.dtsi:117 */
		pwm6: pwm6@40078600 {
			compatible = "renesas,ra-pwm"; /* in zephyr/dts/arm/renesas/ra/ra4/r7fa4m1ax.dtsi:118 */
			divider = < 0x0 >;             /* in zephyr/dts/arm/renesas/ra/ra4/r7fa4m1ax.dtsi:119 */
			channel = < 0x6 >;             /* in zephyr/dts/arm/renesas/ra/ra4/r7fa4m1ax.dtsi:120 */
			clocks = < &pclkd 0x3 0x6 >;   /* in zephyr/dts/arm/renesas/ra/ra4/r7fa4m1ax.dtsi:121 */
			reg = < 0x40078600 0x100 >;    /* in zephyr/dts/arm/renesas/ra/ra4/r7fa4m1ax.dtsi:122 */
			#pwm-cells = < 0x3 >;          /* in zephyr/dts/arm/renesas/ra/ra4/r7fa4m1ax.dtsi:123 */
			status = "disabled";           /* in zephyr/dts/arm/renesas/ra/ra4/r7fa4m1ax.dtsi:124 */
		};

		/* node '/soc/pwm7@40078700' defined in zephyr/dts/arm/renesas/ra/ra4/r7fa4m1ax.dtsi:127 */
		pwm7: pwm7@40078700 {
			compatible = "renesas,ra-pwm"; /* in zephyr/dts/arm/renesas/ra/ra4/r7fa4m1ax.dtsi:128 */
			divider = < 0x0 >;             /* in zephyr/dts/arm/renesas/ra/ra4/r7fa4m1ax.dtsi:129 */
			channel = < 0x7 >;             /* in zephyr/dts/arm/renesas/ra/ra4/r7fa4m1ax.dtsi:130 */
			clocks = < &pclkd 0x3 0x6 >;   /* in zephyr/dts/arm/renesas/ra/ra4/r7fa4m1ax.dtsi:131 */
			reg = < 0x40078700 0x100 >;    /* in zephyr/dts/arm/renesas/ra/ra4/r7fa4m1ax.dtsi:132 */
			#pwm-cells = < 0x3 >;          /* in zephyr/dts/arm/renesas/ra/ra4/r7fa4m1ax.dtsi:133 */
			status = "disabled";           /* in zephyr/dts/arm/renesas/ra/ra4/r7fa4m1ax.dtsi:134 */
		};
	};

	/* node '/cpus' defined in zephyr/dts/arm/renesas/ra/ra4/ra4-cm4-common.dtsi:14 */
	cpus {
		#address-cells = < 0x1 >; /* in zephyr/dts/arm/renesas/ra/ra4/ra4-cm4-common.dtsi:15 */
		#size-cells = < 0x0 >;    /* in zephyr/dts/arm/renesas/ra/ra4/ra4-cm4-common.dtsi:16 */

		/* node '/cpus/cpu@0' defined in zephyr/dts/arm/renesas/ra/ra4/ra4-cm4-common.dtsi:18 */
		cpu@0 {
			device_type = "cpu";          /* in zephyr/dts/arm/renesas/ra/ra4/ra4-cm4-common.dtsi:19 */
			compatible = "arm,cortex-m4"; /* in zephyr/dts/arm/renesas/ra/ra4/ra4-cm4-common.dtsi:20 */
			reg = < 0x0 >;                /* in zephyr/dts/arm/renesas/ra/ra4/ra4-cm4-common.dtsi:21 */
			#address-cells = < 0x1 >;     /* in zephyr/dts/arm/renesas/ra/ra4/ra4-cm4-common.dtsi:22 */
			#size-cells = < 0x1 >;        /* in zephyr/dts/arm/renesas/ra/ra4/ra4-cm4-common.dtsi:23 */

			/* node '/cpus/cpu@0/mpu@e000ed90' defined in zephyr/dts/arm/renesas/ra/ra4/ra4-cm4-common.dtsi:25 */
			mpu: mpu@e000ed90 {
				compatible = "arm,armv7m-mpu"; /* in zephyr/dts/arm/renesas/ra/ra4/ra4-cm4-common.dtsi:26 */
				reg = < 0xe000ed90 0x40 >;     /* in zephyr/dts/arm/renesas/ra/ra4/ra4-cm4-common.dtsi:27 */
			};
		};
	};

	/* node '/usbfs-phy' defined in zephyr/dts/arm/renesas/ra/ra4/ra4-cm4-common.dtsi:519 */
	usbfs_phy: usbfs-phy {
		compatible = "usb-nop-xceiv"; /* in zephyr/dts/arm/renesas/ra/ra4/ra4-cm4-common.dtsi:520 */
		#phy-cells = < 0x0 >;         /* in zephyr/dts/arm/renesas/ra/ra4/ra4-cm4-common.dtsi:521 */
		phandle = < 0x1a >;           /* in zephyr/dts/arm/renesas/ra/ra4/ra4-cm4-common.dtsi:311 */
	};

	/* node '/clocks' defined in zephyr/dts/arm/renesas/ra/ra4/r7fa4m1ax.dtsi:138 */
	clocks: clocks {
		#address-cells = < 0x1 >; /* in zephyr/dts/arm/renesas/ra/ra4/r7fa4m1ax.dtsi:139 */
		#size-cells = < 0x1 >;    /* in zephyr/dts/arm/renesas/ra/ra4/r7fa4m1ax.dtsi:140 */

		/* node '/clocks/clock-main-osc' defined in zephyr/dts/arm/renesas/ra/ra4/r7fa4m1ax.dtsi:142 */
		xtal: clock-main-osc {
			compatible = "renesas,ra-cgc-external-clock"; /* in zephyr/dts/arm/renesas/ra/ra4/r7fa4m1ax.dtsi:143 */
			clock-frequency = < 0xb71b00 >;               /* in zephyr/boards/renesas/ek_ra4m1/ek_ra4m1.dts:55 */
			mosel = < 0x0 >;                              /* in zephyr/boards/renesas/ek_ra4m1/ek_ra4m1.dts:56 */
			#clock-cells = < 0x0 >;                       /* in zephyr/boards/renesas/ek_ra4m1/ek_ra4m1.dts:57 */
			status = "okay";                              /* in zephyr/boards/renesas/ek_ra4m1/ek_ra4m1.dts:58 */
			phandle = < 0x1e >;                           /* in zephyr/boards/renesas/ek_ra4m1/ek_ra4m1.dts:66 */
		};

		/* node '/clocks/clock-hoco' defined in zephyr/dts/arm/renesas/ra/ra4/r7fa4m1ax.dtsi:149 */
		hoco: clock-hoco {
			compatible = "fixed-clock";      /* in zephyr/dts/arm/renesas/ra/ra4/r7fa4m1ax.dtsi:150 */
			clock-frequency = < 0x16e3600 >; /* in zephyr/dts/arm/renesas/ra/ra4/r7fa4m1ax.dtsi:151 */
			#clock-cells = < 0x0 >;          /* in zephyr/dts/arm/renesas/ra/ra4/r7fa4m1ax.dtsi:152 */
		};

		/* node '/clocks/clock-moco' defined in zephyr/dts/arm/renesas/ra/ra4/r7fa4m1ax.dtsi:155 */
		moco: clock-moco {
			compatible = "fixed-clock";     /* in zephyr/dts/arm/renesas/ra/ra4/r7fa4m1ax.dtsi:156 */
			clock-frequency = < 0x7a1200 >; /* in zephyr/dts/arm/renesas/ra/ra4/r7fa4m1ax.dtsi:157 */
			#clock-cells = < 0x0 >;         /* in zephyr/dts/arm/renesas/ra/ra4/r7fa4m1ax.dtsi:158 */
		};

		/* node '/clocks/clock-loco' defined in zephyr/dts/arm/renesas/ra/ra4/r7fa4m1ax.dtsi:161 */
		loco: clock-loco {
			compatible = "fixed-clock";   /* in zephyr/dts/arm/renesas/ra/ra4/r7fa4m1ax.dtsi:162 */
			clock-frequency = < 0x8000 >; /* in zephyr/dts/arm/renesas/ra/ra4/r7fa4m1ax.dtsi:163 */
			#clock-cells = < 0x0 >;       /* in zephyr/dts/arm/renesas/ra/ra4/r7fa4m1ax.dtsi:164 */
		};

		/* node '/clocks/clock-subclk' defined in zephyr/dts/arm/renesas/ra/ra4/r7fa4m1ax.dtsi:167 */
		subclk: clock-subclk {
			compatible = "renesas,ra-cgc-subclk"; /* in zephyr/dts/arm/renesas/ra/ra4/r7fa4m1ax.dtsi:168 */
			clock-frequency = < 0x8000 >;         /* in zephyr/dts/arm/renesas/ra/ra4/r7fa4m1ax.dtsi:169 */
			#clock-cells = < 0x0 >;               /* in zephyr/dts/arm/renesas/ra/ra4/r7fa4m1ax.dtsi:170 */
			status = "okay";                      /* in zephyr/boards/renesas/ek_ra4m1/ek_ra4m1.dts:62 */
		};

		/* node '/clocks/pll' defined in zephyr/dts/arm/renesas/ra/ra4/r7fa4m1ax.dtsi:174 */
		pll: pll {
			compatible = "renesas,ra-cgc-pll"; /* in zephyr/dts/arm/renesas/ra/ra4/r7fa4m1ax.dtsi:175 */
			#clock-cells = < 0x0 >;            /* in zephyr/dts/arm/renesas/ra/ra4/r7fa4m1ax.dtsi:176 */
			clocks = < &xtal >;                /* in zephyr/boards/renesas/ek_ra4m1/ek_ra4m1.dts:66 */
			div = < 0x2 >;                     /* in zephyr/boards/renesas/ek_ra4m1/ek_ra4m1.dts:67 */
			mul = < 0x8 0x0 >;                 /* in zephyr/boards/renesas/ek_ra4m1/ek_ra4m1.dts:68 */
			status = "okay";                   /* in zephyr/boards/renesas/ek_ra4m1/ek_ra4m1.dts:69 */
			phandle = < 0x1f >;                /* in zephyr/dts/arm/renesas/ra/ra4/r7fa4m1ax.dtsi:191 */
		};

		/* node '/clocks/pclkblock@40047000' defined in zephyr/dts/arm/renesas/ra/ra4/r7fa4m1ax.dtsi:184 */
		pclkblock: pclkblock@40047000 {
			compatible = "renesas,ra-cgc-pclk-block"; /* in zephyr/dts/arm/renesas/ra/ra4/r7fa4m1ax.dtsi:185 */
			reg = < 0x40047000 0x4 >,
			      < 0x40047004 0x4 >,
			      < 0x40047008 0x4 >;                 /* in zephyr/dts/arm/renesas/ra/ra4/r7fa4m1ax.dtsi:186 */
			reg-names = "MSTPB",
			            "MSTPC",
			            "MSTPD";                      /* in zephyr/dts/arm/renesas/ra/ra4/r7fa4m1ax.dtsi:189 */
			#clock-cells = < 0x0 >;                   /* in zephyr/dts/arm/renesas/ra/ra4/r7fa4m1ax.dtsi:190 */
			clocks = < &pll >;                        /* in zephyr/dts/arm/renesas/ra/ra4/r7fa4m1ax.dtsi:191 */
			status = "okay";                          /* in zephyr/dts/arm/renesas/ra/ra4/r7fa4m1ax.dtsi:192 */

			/* node '/clocks/pclkblock@40047000/iclk' defined in zephyr/dts/arm/renesas/ra/ra4/r7fa4m1ax.dtsi:194 */
			iclk: iclk {
				compatible = "renesas,ra-cgc-pclk"; /* in zephyr/dts/arm/renesas/ra/ra4/r7fa4m1ax.dtsi:195 */
				clock-frequency = < 0x2dc6c00 >;    /* in zephyr/dts/arm/renesas/ra/ra4/r7fa4m1ax.dtsi:196 */
				div = < 0x1 >;                      /* in zephyr/dts/arm/renesas/ra/ra4/r7fa4m1ax.dtsi:197 */
				#clock-cells = < 0x2 >;             /* in zephyr/dts/arm/renesas/ra/ra4/r7fa4m1ax.dtsi:198 */
				status = "okay";                    /* in zephyr/dts/arm/renesas/ra/ra4/r7fa4m1ax.dtsi:199 */
				phandle = < 0x13 >;                 /* in zephyr/dts/arm/renesas/ra/ra4/ra4-cm4-common.dtsi:131 */
			};

			/* node '/clocks/pclkblock@40047000/pclka' defined in zephyr/dts/arm/renesas/ra/ra4/r7fa4m1ax.dtsi:202 */
			pclka: pclka {
				compatible = "renesas,ra-cgc-pclk"; /* in zephyr/dts/arm/renesas/ra/ra4/r7fa4m1ax.dtsi:203 */
				div = < 0x1 >;                      /* in zephyr/dts/arm/renesas/ra/ra4/r7fa4m1ax.dtsi:204 */
				#clock-cells = < 0x2 >;             /* in zephyr/dts/arm/renesas/ra/ra4/r7fa4m1ax.dtsi:205 */
				status = "okay";                    /* in zephyr/dts/arm/renesas/ra/ra4/r7fa4m1ax.dtsi:206 */
				phandle = < 0x14 >;                 /* in zephyr/dts/arm/renesas/ra/ra4/ra4-cm4-common.dtsi:148 */
			};

			/* node '/clocks/pclkblock@40047000/pclkb' defined in zephyr/dts/arm/renesas/ra/ra4/r7fa4m1ax.dtsi:209 */
			pclkb: pclkb {
				compatible = "renesas,ra-cgc-pclk"; /* in zephyr/dts/arm/renesas/ra/ra4/r7fa4m1ax.dtsi:210 */
				div = < 0x2 >;                      /* in zephyr/dts/arm/renesas/ra/ra4/r7fa4m1ax.dtsi:211 */
				#clock-cells = < 0x2 >;             /* in zephyr/dts/arm/renesas/ra/ra4/r7fa4m1ax.dtsi:212 */
				status = "okay";                    /* in zephyr/dts/arm/renesas/ra/ra4/r7fa4m1ax.dtsi:213 */
				phandle = < 0x2 >;                  /* in zephyr/dts/arm/renesas/ra/ra4/ra4-cm4-common.dtsi:43 */
			};

			/* node '/clocks/pclkblock@40047000/pclkc' defined in zephyr/dts/arm/renesas/ra/ra4/r7fa4m1ax.dtsi:216 */
			pclkc: pclkc {
				compatible = "renesas,ra-cgc-pclk"; /* in zephyr/dts/arm/renesas/ra/ra4/r7fa4m1ax.dtsi:217 */
				div = < 0x1 >;                      /* in zephyr/dts/arm/renesas/ra/ra4/r7fa4m1ax.dtsi:218 */
				#clock-cells = < 0x2 >;             /* in zephyr/dts/arm/renesas/ra/ra4/r7fa4m1ax.dtsi:219 */
				status = "okay";                    /* in zephyr/dts/arm/renesas/ra/ra4/r7fa4m1ax.dtsi:220 */
			};

			/* node '/clocks/pclkblock@40047000/pclkd' defined in zephyr/dts/arm/renesas/ra/ra4/r7fa4m1ax.dtsi:223 */
			pclkd: pclkd {
				compatible = "renesas,ra-cgc-pclk"; /* in zephyr/dts/arm/renesas/ra/ra4/r7fa4m1ax.dtsi:224 */
				div = < 0x1 >;                      /* in zephyr/dts/arm/renesas/ra/ra4/r7fa4m1ax.dtsi:225 */
				#clock-cells = < 0x2 >;             /* in zephyr/dts/arm/renesas/ra/ra4/r7fa4m1ax.dtsi:226 */
				status = "okay";                    /* in zephyr/dts/arm/renesas/ra/ra4/r7fa4m1ax.dtsi:227 */
				phandle = < 0x1c >;                 /* in zephyr/dts/arm/renesas/ra/ra4/ra4-cm4-common.dtsi:424 */
			};

			/* node '/clocks/pclkblock@40047000/fclk' defined in zephyr/dts/arm/renesas/ra/ra4/r7fa4m1ax.dtsi:230 */
			fclk: fclk {
				compatible = "renesas,ra-cgc-pclk"; /* in zephyr/dts/arm/renesas/ra/ra4/r7fa4m1ax.dtsi:231 */
				div = < 0x2 >;                      /* in zephyr/dts/arm/renesas/ra/ra4/r7fa4m1ax.dtsi:232 */
				#clock-cells = < 0x2 >;             /* in zephyr/dts/arm/renesas/ra/ra4/r7fa4m1ax.dtsi:233 */
				status = "okay";                    /* in zephyr/dts/arm/renesas/ra/ra4/r7fa4m1ax.dtsi:234 */
			};

			/* node '/clocks/pclkblock@40047000/clkout' defined in zephyr/dts/arm/renesas/ra/ra4/r7fa4m1ax.dtsi:237 */
			clkout: clkout {
				compatible = "renesas,ra-cgc-pclk"; /* in zephyr/dts/arm/renesas/ra/ra4/r7fa4m1ax.dtsi:238 */
				#clock-cells = < 0x2 >;             /* in zephyr/dts/arm/renesas/ra/ra4/r7fa4m1ax.dtsi:239 */
				status = "disabled";                /* in zephyr/dts/arm/renesas/ra/ra4/r7fa4m1ax.dtsi:240 */
			};

			/* node '/clocks/pclkblock@40047000/uclk' defined in zephyr/dts/arm/renesas/ra/ra4/r7fa4m1ax.dtsi:243 */
			uclk: uclk {
				compatible = "renesas,ra-cgc-pclk"; /* in zephyr/dts/arm/renesas/ra/ra4/r7fa4m1ax.dtsi:244 */
				#clock-cells = < 0x2 >;             /* in zephyr/dts/arm/renesas/ra/ra4/r7fa4m1ax.dtsi:245 */
				status = "disabled";                /* in zephyr/dts/arm/renesas/ra/ra4/r7fa4m1ax.dtsi:246 */
				phandle = < 0x1b >;                 /* in zephyr/dts/arm/renesas/ra/ra4/ra4-cm4-common.dtsi:312 */
			};
		};
	};

	/* node '/leds' defined in zephyr/boards/renesas/ek_ra4m1/ek_ra4m1.dts:28 */
	leds {
		compatible = "gpio-leds"; /* in zephyr/boards/renesas/ek_ra4m1/ek_ra4m1.dts:29 */

		/* node '/leds/led1' defined in zephyr/boards/renesas/ek_ra4m1/ek_ra4m1.dts:31 */
		led1: led1 {
			gpios = < &ioport1 0x6 0x0 >; /* in zephyr/boards/renesas/ek_ra4m1/ek_ra4m1.dts:32 */
			label = "LED1";               /* in zephyr/boards/renesas/ek_ra4m1/ek_ra4m1.dts:33 */
		};
	};

	/* node '/buttons' defined in zephyr/boards/renesas/ek_ra4m1/ek_ra4m1.dts:37 */
	buttons {
		compatible = "gpio-keys"; /* in zephyr/boards/renesas/ek_ra4m1/ek_ra4m1.dts:38 */

		/* node '/buttons/s1' defined in zephyr/boards/renesas/ek_ra4m1/ek_ra4m1.dts:40 */
		button0: s1 {
			gpios = < &ioport1 0x5 0x11 >;  /* in zephyr/boards/renesas/ek_ra4m1/ek_ra4m1.dts:41 */
			label = "Push button switch 1"; /* in zephyr/boards/renesas/ek_ra4m1/ek_ra4m1.dts:42 */
			zephyr,code = < 0xb >;          /* in zephyr/boards/renesas/ek_ra4m1/ek_ra4m1.dts:43 */
		};
	};
};
